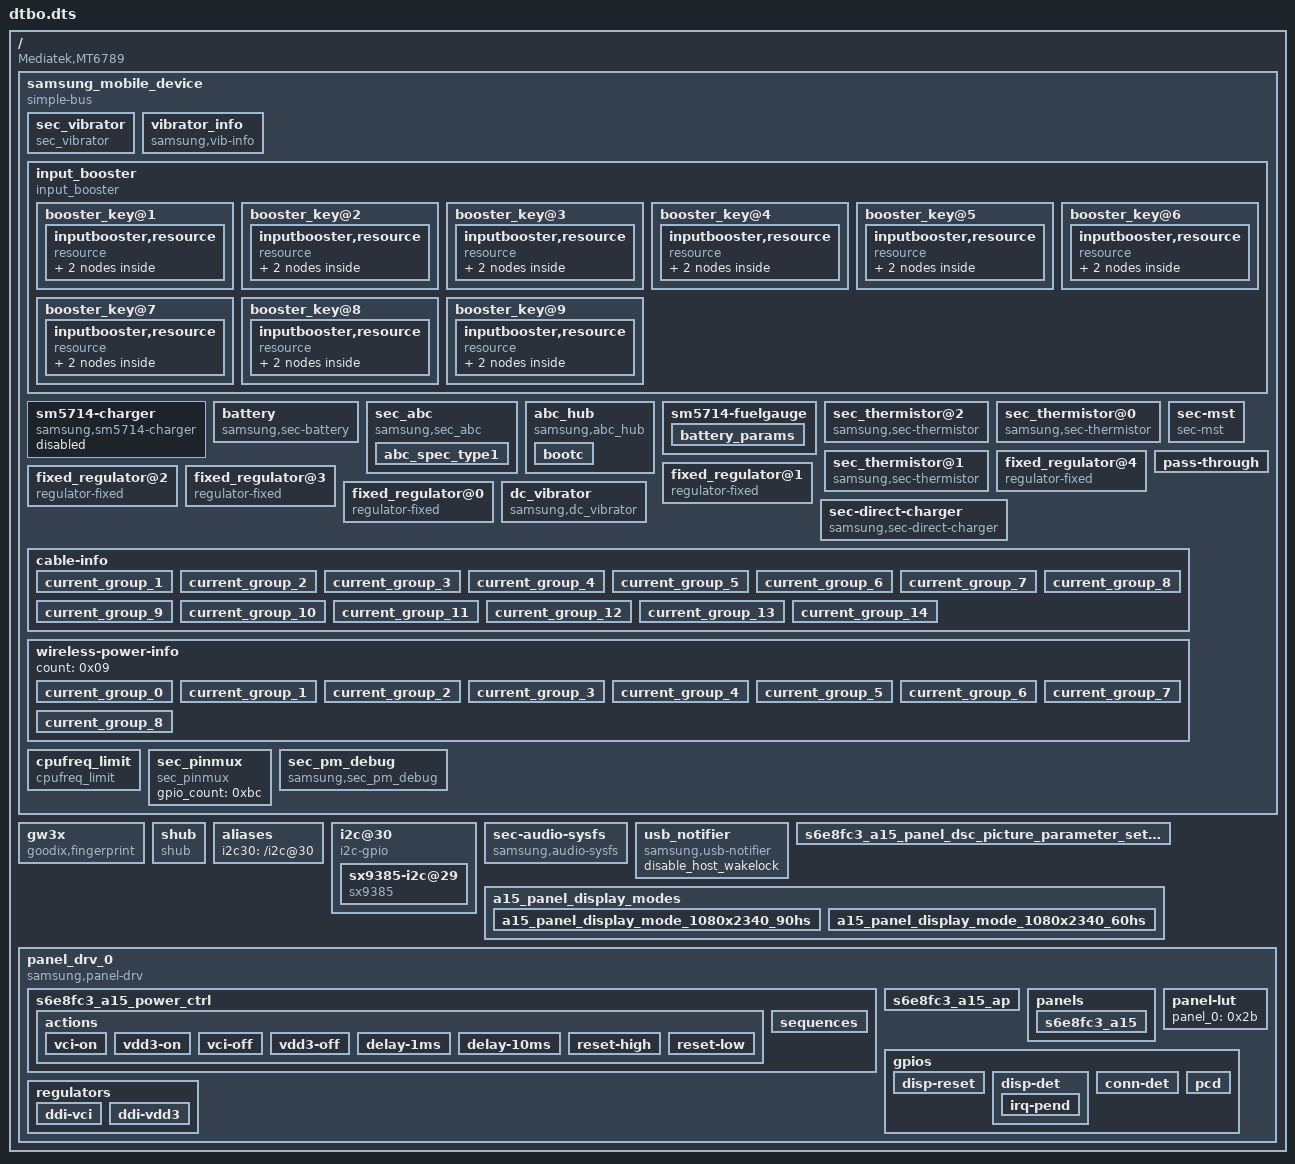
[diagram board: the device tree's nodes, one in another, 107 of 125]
/dts-v1/;

/ {
	compatible = "Mediatek,MT6789\0Samsung,A15 EUR OPEN 00";
	dtbo-hw_rev = <0x00>;
	dtbo-hw_rev_end = <0x03>;

	fragment@smd {
		target-path = "/";

		__overlay__ {

			samsung_mobile_device {
				compatible = "simple-bus";
				phandle = <0x80>;

				sec_vibrator {
					status = "okay";
					compatible = "sec_vibrator";
					haptic,normal_ratio = <0x64>;
					haptic,high_temp_ref = <0x30>;
					haptic,high_temp_ratio = <0x41>;
				};

				vibrator_info {
					status = "okay";
					compatible = "samsung,vib-info";
					functions = [00];
					samsung,intensities;
					samsung,haptic_intensities;
					phandle = <0x81>;
				};

				input_booster {
					status = "okay";
					compatible = "input_booster";
					resValcount = "2";
					max_resource_count = "3";
					max_cluster_count = "3";
					#address-cells = <0x01>;
					#size-cells = <0x00>;
					cpu_cluster_policy = "6,0";
					ib_release_values = "-1,16,0";
					allowed_resources = "0,1";

					booster_key@1 {
						input_booster,label = "key";
						input_booster,type = <0x00>;
						input_booster,head_time = <0xc8>;
						input_booster,tail_time = <0x00>;

						inputbooster,resource {
							compatible = "resource";

							resource@1 {
								resource,label = "CPU";
								resource,value = <0x137090 0x00>;
							};

							resource@2 {
								resource,label = "DDR";
								resource,value = <0x00 0x00>;
							};
						};
					};

					booster_key@2 {
						input_booster,label = "touchkey";
						input_booster,type = <0x01>;
						input_booster,head_time = <0x01>;
						input_booster,tail_time = <0x12c>;

						inputbooster,resource {
							compatible = "resource";

							resource@1 {
								resource,label = "CPU";
								resource,value = <0x00 0x106800>;
							};

							resource@2 {
								resource,label = "DDR";
								resource,value = <0x00 0x00>;
							};
						};
					};

					booster_key@3 {
						input_booster,label = "touch";
						input_booster,type = <0x02>;
						input_booster,head_time = <0x82>;
						input_booster,tail_time = <0x1f4>;

						inputbooster,resource {
							compatible = "resource";

							resource@1 {
								resource,label = "CPU";
								resource,value = <0x137090 0x106800>;
							};

							resource@2 {
								resource,label = "DDR";
								resource,value = <0x10aa 0x10aa>;
							};
						};
					};

					booster_key@4 {
						input_booster,label = "multitouch";
						input_booster,type = <0x03>;
						input_booster,head_time = <0x3e8>;
						input_booster,tail_time = <0x1f4>;

						inputbooster,resource {
							compatible = "resource";

							resource@1 {
								resource,label = "CPU";
								resource,value = <0x137090 0x106800>;
							};

							resource@2 {
								resource,label = "DDR";
								resource,value = <0x00 0x00>;
							};
						};
					};

					booster_key@5 {
						input_booster,label = "keyboard";
						input_booster,type = <0x04>;
						input_booster,head_time = <0x82>;
						input_booster,tail_time = <0x82>;

						inputbooster,resource {
							compatible = "resource";

							resource@1 {
								resource,label = "CPU";
								resource,value = <0x106800 0x106800>;
							};

							resource@2 {
								resource,label = "DDR";
								resource,value = <0x00 0x00>;
							};
						};
					};

					booster_key@6 {
						input_booster,label = "MOUSE";
						input_booster,type = <0x05>;
						input_booster,head_time = <0xc8>;
						input_booster,tail_time = <0x12c>;

						inputbooster,resource {
							compatible = "resource";

							resource@1 {
								resource,label = "CPU";
								resource,value = <0x137090 0x106800>;
							};

							resource@2 {
								resource,label = "DDR";
								resource,value = <0x00 0x00>;
							};
						};
					};

					booster_key@7 {
						input_booster,label = "mouse_wheel";
						input_booster,type = <0x06>;
						input_booster,head_time = <0xc8>;
						input_booster,tail_time = <0x00>;

						inputbooster,resource {
							compatible = "resource";

							resource@1 {
								resource,label = "CPU";
								resource,value = <0x137090 0x00>;
							};

							resource@2 {
								resource,label = "DDR";
								resource,value = <0x00 0x00>;
							};
						};
					};

					booster_key@8 {
						input_booster,label = "pen_hover";
						input_booster,type = <0x07>;
						input_booster,head_time = <0xc8>;
						input_booster,tail_time = <0x12c>;

						inputbooster,resource {
							compatible = "resource";

							resource@1 {
								resource,label = "CPU";
								resource,value = <0x137090 0x106800>;
							};

							resource@2 {
								resource,label = "DDR";
								resource,value = <0x00 0x00>;
							};
						};
					};

					booster_key@9 {
						input_booster,label = "pen";
						input_booster,type = <0x08>;
						input_booster,head_time = <0xc8>;
						input_booster,tail_time = <0x258>;

						inputbooster,resource {
							compatible = "resource";

							resource@1 {
								resource,label = "CPU";
								resource,value = <0x1a3ec0 0x106800>;
							};

							resource@2 {
								resource,label = "DDR";
								resource,value = <0x00 0x00>;
							};
						};
					};
				};

				sm5714-charger {
					status = "disable";
					compatible = "samsung,sm5714-charger";
					sm5714,chg_float_voltage_down_en = <0x01>;
					sm5714,chg_float_voltage_down_offset_mv = <0x14>;
					phandle = <0x82>;
				};

				battery {
					battery,otg_name = "sm5714-otg";
					battery,fgsrc_switch_name = "sm5714-fuelgauge";
					status = "okay";
					compatible = "samsung,sec-battery";
					battery,vendor = "Battery";
					battery,charger_name = "sec-direct-charger";
					battery,fuelgauge_name = "sm5714-fuelgauge";
					battery,technology = <0x02>;
					battery,chip_vendor = "MTK";
					battery,batt_data_version = <0x01>;
					battery,adc_check_count = <0x05>;
					battery,temp_check_type = <0x02>;
					battery,usb_temp_check_type = <0x02>;
					battery,chg_temp_check_type = <0x02>;
					battery,wpc_temp_check_type = <0x00>;
					battery,lrp_temp_check_type = <0x02>;
					battery,thermal_source = <0x02>;
					battery,usb_thermal_source = <0x02>;
					battery,chg_thermal_source = <0x02>;
					battery,wpc_thermal_source = <0x00>;
					battery,inbat_ocv_type = <0x00>;
					battery,polling_time = <0x0a 0x1e 0x1e 0x1e 0xe10>;
					battery,cable_check_type = <0x04>;
					battery,cable_source_type = <0x01>;
					battery,polling_type = <0x01>;
					battery,monitor_initial_count = <0x00>;
					battery,battery_check_type = <0x00>;
					battery,ovp_uvlo_check_type = <0x03>;
					battery,temp_check_count = <0x01>;
					battery,usb_protection_temp = <0x1f4>;
					battery,temp_gap_bat_usb = <0x96>;
					battery,overheatlimit_threshold = <0x2bc>;
					battery,overheatlimit_recovery = <0x2a8>;
					battery,wire_warm_overheat_thresh = <0x1f4>;
					battery,wire_normal_warm_thresh = <0x1a4>;
					battery,wire_cool1_normal_thresh = <0xb4>;
					battery,wire_cool2_cool1_thresh = <0x96>;
					battery,wire_cool3_cool2_thresh = <0x32>;
					battery,wire_cold_cool3_thresh = <0x00>;
					battery,wireless_warm_overheat_thresh = <0x1f4>;
					battery,wireless_normal_warm_thresh = <0x1a4>;
					battery,wireless_cool1_normal_thresh = <0xb4>;
					battery,wireless_cool2_cool1_thresh = <0x96>;
					battery,wireless_cool3_cool2_thresh = <0x32>;
					battery,wireless_cold_cool3_thresh = <0x00>;
					battery,tx_high_threshold = <0x1f4>;
					battery,tx_high_recovery = <0x1c2>;
					battery,tx_low_threshold = <0x00>;
					battery,tx_low_recovery = <0x32>;
					battery,wire_warm_current = <0xdac>;
					battery,wire_cool1_current = <0xc4e>;
					battery,wire_cool2_current = <0x47e>;
					battery,wire_cool3_current = <0x1c2>;
					battery,wireless_warm_current = <0x418>;
					battery,wireless_cool1_current = <0xc4a>;
					battery,wireless_cool2_current = <0x418>;
					battery,wireless_cool3_current = <0x1b5>;
					battery,full_check_type = <0x02>;
					battery,full_check_type_2nd = <0x02>;
					battery,full_check_count = <0x01>;
					battery,chg_gpio_full_check = <0x00>;
					battery,chg_polarity_full_check = <0x01>;
					battery,chg_high_temp = <0x24e>;
					battery,chg_high_temp_recovery = <0x226>;
					battery,chg_input_limit_current = <0x3e8>;
					battery,chg_charging_limit_current = <0x960>;
					battery,dchg_high_temp = <0x3e8 0x3e8 0x24e 0x24e>;
					battery,dchg_high_temp_recovery = <0x3e8 0x3e8 0x226 0x226>;
					battery,dchg_high_batt_temp = <0x3e8 0x3e8 0x3e8 0x3e8>;
					battery,dchg_high_batt_temp_recovery = <0x3e8 0x3e8 0x3e8 0x3e8>;
					battery,dchg_input_limit_current = <0x3e8>;
					battery,dchg_charging_limit_current = <0x7d0>;
					battery,wpc_temp_control_source = <0x01>;
					battery,wpc_high_temp = <0x190>;
					battery,wpc_high_temp_recovery = <0x17c>;
					battery,wpc_input_limit_current = <0x320>;
					battery,wpc_charging_limit_current = <0x3e8>;
					battery,wpc_temp_lcd_on_control_source = <0x01>;
					battery,wpc_lcd_on_input_limit_current = <0x320>;
					battery,wpc_store_high_temp = <0x168>;
					battery,wpc_store_high_temp_recovery = <0x154>;
					battery,wpc_store_charging_limit_current = <0x190>;
					battery,wpc_store_lcd_on_high_temp = <0x168>;
					battery,wpc_store_lcd_on_high_temp_rec = <0x12c>;
					battery,wpc_store_lcd_on_charging_limit_current = <0x190>;
					battery,fcc_by_tx = <0x4b0>;
					battery,sleep_mode_limit_current = <0x320>;
					battery,wc_full_input_limit_current = <0x64>;
					battery,ta_alert_wa;
					battery,mix_high_temp = <0x1a4>;
					battery,mix_high_chg_temp = <0x1f4>;
					battery,mix_high_temp_recovery = <0x186>;
					battery,mix_v2_lrp_recov = <0x1cc>;
					battery,mix_v2_lrp_cond = <0x1e0>;
					battery,mix_v2_bat_cond = <0x1e0>;
					battery,mix_v2_chg_cond = <0x00>;
					battery,mix_v2_dchg_cond = <0x00>;
					battery,full_condition_type = <0x09>;
					battery,full_condition_soc = <0x5d>;
					battery,recharge_check_count = <0x01>;
					battery,recharge_condition_type = <0x04>;
					battery,recharge_condition_soc = <0x62>;
					battery,charging_reset_time = <0x00>;
					battery,chg_float_voltage = <0x111c>;
					battery,pre_afc_work_delay = <0x7d0>;
					battery,pre_wc_afc_work_delay = <0xfa0>;
					battery,pre_afc_input_current = <0x1f4>;
					battery,pre_wc_afc_input_current = <0x1f4>;
					battery,swelling_high_rechg_voltage = <0xfa0>;
					battery,siop_icl = <0x4b0>;
					battery,siop_fcc = <0x708>;
					battery,siop_hv_icl = <0x2bc>;
					battery,siop_hv_icl_2nd = <0x226>;
					battery,siop_hv_fcc = <0x708>;
					battery,siop_apdo_icl = <0x3e8>;
					battery,siop_apdo_fcc = <0x7d0>;
					battery,siop_wpc_icl = <0x258>;
					battery,siop_wpc_fcc = <0x3e8 0x1f4 0x64>;
					battery,siop_hv_wpc_icl = <0x2bc>;
					battery,siop_hv_wpc_fcc = <0x3e8 0x1f4 0x64>;
					battery,siop_store_hv_wpc_icl = <0x1c2>;
					battery,store_mode_buckoff;
					battery,temp_table_LRP_45W = <0x181 0x16d>;
					battery,rp_current_rp1 = <0x1f4>;
					battery,rp_current_rp2 = <0x5dc>;
					battery,rp_current_rp3 = <0xbb8>;
					battery,rp_current_rdu_rp3 = <0x834>;
					battery,rp_current_abnormal_rp3 = <0x708>;
					battery,pd_charging_charge_power = <0x3a98>;
					battery,max_charging_current = <0xc4e>;
					battery,store_mode_charging_max = <0x46>;
					battery,store_mode_charging_min = <0x3c>;
					battery,wireless_cc_cv = <0x55>;
					battery,wireless_otg_input_current = <0x384>;
					battery,age_data_cycle = <0x00 0xc8 0xfa 0x12c 0x3e9>;
					battery,age_data_full_condition_soc = <0x5d 0x5c 0x5b 0x5a 0x59>;
					battery,age_data_common_offset = <0x00 0x14 0x28 0x3c 0x6e>;
					battery,age_data = <0x00 0x10fe 0x10b8 0x109a 0x5d 0x12c 0x10ea 0x10a4 0x1086 0x5c 0x190 0x10d6 0x1090 0x1072 0x5b 0x2bc 0x10c2 0x107c 0x105e 0x5a 0x3e8 0x1090 0x104a 0x102c 0x59>;
					battery,health_condition_cycle = <0x384 0x4b0 0x5dc>;
					battery,health_condition_asoc = <0x00 0x00 0x00>;
					battery,max_input_voltage = <0x2328>;
					battery,max_input_current = <0xbb8>;
					battery,cisd_alg_index = <0x08>;
					battery,cisd_max_voltage_thr = <0x1388>;
					battery,ignore_cisd_index = <0x00 0x00>;
					battery,ignore_cisd_index_d = <0x00 0x50>;
					battery,expired_time = <0x2580>;
					battery,recharging_expired_time = <0x1518>;
					battery,battery_full_capacity = <0x1388>;
					battery,ttf_capacity = <0x1324>;
					battery,cv_data = <0xe79 0x352 0x6cc 0xe56 0x366 0x668 0xbe0 0x37a 0x604 0x9ba 0x38e 0x582 0x77d 0x3a2 0x4d8 0x55a 0x3b6 0x3f2 0x416 0x3ca 0x2d0 0x289 0x3de 0xa5 0x1e4 0x3e8 0x00>;
					io-channels = <0xffffffff 0x03 0xffffffff 0x06 0xffffffff 0x05>;
					io-channel-names = "adc-temp\0adc-chg-temp\0adc-usb-temp\0n/a\0n/a\0n/a\0n/a\0n/a";
					pinctrl-names = "default";
					battery,adc_read_type = <0x01>;
					battery,dchg_temp_check_type = <0x02>;
					battery,dchg_thermal_source = <0x02>;
					battery,dctp_by_cgtp;
					battery,temp_adc_rsense = <0x0f>;
					battery,temp_table_adc = <0x65 0x71 0x8b 0xa5 0xc2 0xe1 0x10e 0x141 0x18d 0x1e4 0x242 0x2c8 0x358 0x402 0x4ca 0x59f 0x6a0 0x793 0x938 0xa93 0xbc4 0xd20 0xe29>;
					battery,temp_table_data = <0x384 0x352 0x320 0x2ee 0x2bc 0x28a 0x258 0x226 0x1f4 0x1c2 0x190 0x15e 0x12c 0xfa 0xc8 0x96 0x64 0x32 0x00 0xffffffce 0xffffff9c 0xffffff6a 0xffffff38>;
					battery,usb_temp_table_adc = <0x175 0x1ae 0x1f6 0x249 0x2a6 0x302 0x389 0x41b 0x4e2 0x5b7 0x68a 0x79c 0x8a1 0x9b3 0xacc 0xbcd 0xcde 0xdb1 0xef5 0xfd2 0x1026 0x1026 0x1026>;
					battery,usb_temp_table_data = <0x384 0x352 0x320 0x2ee 0x2bc 0x28a 0x258 0x226 0x1f4 0x1c2 0x190 0x15e 0x12c 0xfa 0xc8 0x96 0x64 0x32 0x00 0xffffffce 0xffffff9c 0xffffff6a 0xffffff38>;
					battery,chg_temp_table_adc = <0x168 0x19e 0x1e9 0x23a 0x296 0x2fb 0x380 0x410 0x4cd 0x59e 0x675 0x78c 0x891 0x9a6 0xabf 0xbbb 0xcd3 0xd9d 0xee1 0xfc5 0x1026 0x1026 0x1026>;
					battery,chg_temp_table_data = <0x384 0x352 0x320 0x2ee 0x2bc 0x28a 0x258 0x226 0x1f4 0x1c2 0x190 0x15e 0x12c 0xfa 0xc8 0x96 0x64 0x32 0x00 0xffffffce 0xffffff9c 0xffffff6a 0xffffff38>;
					battery,support_usb_conn_check;
					battery,mass_with_usb_thm;
					battery,temp_table_LRP_NORMAL = <0x190 0x186 0x186 0x17c 0x186 0x17c 0x17c 0x172 0x3e8 0x960 0x4b0 0x708>;
					battery,temp_table_LRP_25W = <0x19a 0x190 0x186 0x17c 0x190 0x186 0x17c 0x172 0x6a4 0xd48 0x44c 0x898>;
					battery,high_temp_float = <0x1036>;
					battery,low_temp_float = <0x111c>;
					battery,chg_ocp_current = <0x00>;
					battery,max_charging_charge_power = <0x61a8>;
					battery,age_data_by_common_offset;
					battery,step_chg_type = <0x00>;
					battery,dc_step_chg_type = <0xe9>;
					battery,dc_step_chg_charge_power = <0x55f0>;
					battery,dc_step_chg_step = <0x03>;
					battery,dc_step_chg_cond_vol = <0x1004 0x1068 0x111c>;
					battery,dc_step_chg_val_vfloat = <0x1004 0x1068 0x111c>;
					battery,dc_step_chg_val_iout = <0x15a4 0x12a2 0xeec>;
					battery,dc_step_chg_iin_check_cnt = <0x03>;
					battery,dc_step_chg_cond_soc = <0x19 0x35 0x64>;
					battery,standard_curr = <0xeec>;
					battery,ttf_hv_charge_current = <0x9cd>;
					battery,ttf_dc25_charge_current = <0x12c0>;
					battery,support_vpdo;
					battery,dchg_dc_in_swelling;
					battery,boosting_voltage_aicl;
					phandle = <0x83>;
				};

				sec_abc {
					compatible = "samsung,sec_abc";
					status = "okay";

					abc_spec_type1 {
						module_list = "gpu\0gpu_qc\0gpu_qc\0camera\0camera\0vib\0tsp\0tsp_sub\0mm\0camera\0camera\0camera\0camera\0camera\0camera\0camera\0camera\0camera";
						name_list = "gpu_fault\0gpu_fault\0gpu_page_fault\0mipi_overflow\0i2c_fail\0int_gnd_short\0tsp_int_fault\0tsp_int_fault\0venus_hung\0mipi_error_rw1\0mipi_error_rs1\0mipi_error_rt1\0mipi_error_fw1\0mipi_error_rt2\0mipi_error_uw1\0mipi_error_rm1\0mipi_error_rb1\0mipi_error_fs1";
						threshold_cnt = <0x14 0x02 0x14 0x01 0x01 0x19 0x0a 0x0a 0x0a 0x01 0x01 0x01 0x01 0x01 0x01 0x01 0x01 0x01>;
						threshold_time = <0x4b0 0x4b0 0x4b0 0x00 0x00 0x05 0x05 0x05 0x03 0x00 0x00 0x00 0x00 0x00 0x00 0x00 0x00 0x00>;
					};
				};

				abc_hub {
					compatible = "samsung,abc_hub";
					status = "okay";

					bootc {
						bootc,time_spec_user = <0x186a0>;
						bootc,time_spec_eng = <0x249f0>;
						bootc,time_spec_fac = <0x186a0>;
					};
				};

				sm5714-fuelgauge {
					status = "okay";
					fuelgauge,fuel_alert_soc = <0x01>;
					fuelgauge,capacity_max = <0x3e8>;
					fuelgauge,capacity_max_margin = <0x12c>;
					fuelgauge,capacity_min = <0x00>;
					fuelgauge,capacity_calculation_type = <0x1f>;
					fuelgauge,using_temp_compensation;
					fuelgauge,low_temp_limit = <0x64>;
					fuelgauge,using_hw_vempty;
					fuelgauge,sw_v_empty_voltage = <0xc80>;
					fuelgauge,sw_v_empty_voltage_cisd = <0xc1c>;
					fuelgauge,sw_v_empty_recover_voltage = <0xd98>;
					fuelgauge,capacity = <0xfa0>;
					fuelgauge,bat_id_gpio = <0xffffffff 0x6a 0x00 0xffffffff 0x1b 0x00>;
					phandle = <0x84>;

					battery_params {
						battery,id = <0x03>;
						battery3,battery_type = <0x111c 0x25fc>;
						battery3,battery_table0 = <0x1400 0x1b09 0x1b92 0x1c50 0x1cd1 0x1d2f 0x1d6a 0x1d7f 0x1d8f 0x1db7 0x1dee 0x1e39 0x1e6d 0x1ec1 0x1f07 0x1f51 0x1fbe 0x1fce 0x1ff8 0x2095 0x20b0 0x2152 0x229a 0x2400>;
						battery3,battery_table1 = <0x00 0xb3 0x133 0x24c 0x34c 0x44c 0x54c 0x766 0xc00 0xe80 0x13b3 0x1de6 0x2819 0x3266 0x3780 0x3a00 0x41b3 0x444c 0x46cc 0x4be6 0x4e80 0x5633 0x6400 0x64e6>;
						battery3,battery_table2 = <0x4a6f 0x383e 0x3234 0x2c2e 0x292a 0x2727 0x2628 0x2525 0x4a6f 0x383e 0x3234 0x2c2e 0x292a 0x2727 0x2628 0x2525>;
						battery3,rs_value = <0x48 0x48 0x3800 0x10a 0x599 0x599 0x50>;
						battery3,v_alarm = <0xc1c 0xc8>;
						battery3,topoff = <0x1ea>;
						battery3,i_cal = <0x01 0x00 0x800 0x800 0x00 0x00 0x7c9 0x800>;
						battery3,v_cal = <0x01 0x00 0x00 0x01 0x00 0x00 0x00>;
						battery3,temp_std = <0x19>;
						battery3,tem_poff = <0xd7a 0x32 0xd7a 0x32>;
						battery3,aux_ctrl = <0x322 0x5800>;
						battery3,data_ver = <0x02>;
						battery3,v_max_table = <0x229a 0x2271 0x2248 0x2220 0x21bf>;
						battery3,q_max_table = <0x25fc 0x25cf 0x25a2 0x2575 0x2277>;
						battery2,battery_type = <0x111c 0x2581>;
						battery2,battery_table0 = <0x1400 0x1ae0 0x1bd1 0x1c6d 0x1cde 0x1d38 0x1d6c 0x1d7f 0x1d89 0x1dda 0x1e15 0x1e41 0x1e6a 0x1ea4 0x1ef7 0x1f1f 0x1f68 0x1f9d 0x200a 0x2052 0x20eb 0x215c 0x22a8 0x2400>;
						battery2,battery_table1 = <0x00 0x80 0x199 0x299 0x3b3 0x4b3 0x5cc 0x7cc 0xb80 0x124c 0x1a19 0x1f4c 0x2719 0x2ee6 0x36b3 0x394c 0x3be6 0x3e80 0x464c 0x48e6 0x50b3 0x55e6 0x6400 0x64e6>;
						battery2,battery_table2 = <0x4862 0x383d 0x3234 0x2c2e 0x292a 0x2728 0x2627 0x2828 0x4862 0x383d 0x3234 0x2c2e 0x292a 0x2728 0x2627 0x2828>;
						battery2,rs_value = <0x48 0x48 0x3800 0x10a 0x599 0x599 0x50>;
						battery2,v_alarm = <0xc1c 0xc8>;
						battery2,topoff = <0x1ea>;
						battery2,i_cal = <0x01 0x00 0x800 0x800 0x00 0x00 0x7d8 0x800>;
						battery2,v_cal = <0x01 0x00 0x00 0x01 0x00 0x00 0x00>;
						battery2,temp_std = <0x19>;
						battery2,tem_poff = <0xd7a 0x32 0xd7a 0x32>;
						battery2,aux_ctrl = <0x322 0x5800>;
						battery2,data_ver = <0x03>;
						battery2,v_max_table = <0x22a8 0x227f 0x2256 0x222d 0x21cf>;
						battery2,q_max_table = <0x2581 0x2555 0x2529 0x24fc 0x2268>;
						battery1,battery_type = <0x111c 0x2525>;
						battery1,battery_table0 = <0x1400 0x1aad 0x1b4a 0x1c1c 0x1cab 0x1d10 0x1d5b 0x1d6c 0x1d7b 0x1d87 0x1ddb 0x1e17 0x1e42 0x1e90 0x1ed9 0x1f25 0x1f72 0x1f9e 0x1fee 0x207f 0x20e9 0x215a 0x22a5 0x2400>;
						battery1,battery_table1 = <0x00 0x66 0xe6 0x200 0x300 0x419 0x519 0x599 0x733 0xb66 0x1219 0x1a00 0x1f33 0x2c33 0x3400 0x3933 0x3be6 0x3e80 0x43b3 0x4b80 0x50b3 0x55e6 0x6400 0x64e6>;
						battery1,battery_table2 = <0x4965 0x383e 0x3134 0x2b2e 0x2729 0x2526 0x2424 0x2323 0x4965 0x383e 0x3134 0x2b2e 0x2729 0x2526 0x2424 0x2323>;
						battery1,rs_value = <0x48 0x48 0x3800 0x10a 0x599 0x599 0x50>;
						battery1,v_alarm = <0xc1c 0xc8>;
						battery1,topoff = <0x1ea>;
						battery1,i_cal = <0x01 0x00 0x800 0x800 0x00 0x00 0x7c9 0x800>;
						battery1,v_cal = <0x01 0x00 0x00 0x01 0x00 0x00 0x00>;
						battery1,temp_std = <0x19>;
						battery1,tem_poff = <0xd7a 0x32 0xd7a 0x32>;
						battery1,aux_ctrl = <0x322 0x5800>;
						battery1,data_ver = <0x03>;
						battery1,v_max_table = <0x22a5 0x227c 0x2253 0x222a 0x21ce>;
						battery1,q_max_table = <0x2525 0x24f9 0x24cd 0x24a1 0x21c1>;
					};
				};

				sec_thermistor@2 {
					compatible = "samsung,sec-thermistor";
					status = "okay";
					thermistor_name = "sec-wf-thermistor";
					id = <0x02>;
					io-channels = <0xffffffff 0x04>;
					io-channel-names = "wf_therm";
					io-channel-ranges;
					adc_array = <0x16a 0x19d 0x1ea 0x23c 0x297 0x2fd 0x37d 0x40c 0x4cd 0x59a 0x674 0x787 0x88f 0x99f 0xab9 0xbb6 0xcca 0xd9d 0xee1 0xfc2 0x1026 0x1026 0x1026>;
					temp_array = <0x384 0x352 0x320 0x2ee 0x2bc 0x28a 0x258 0x226 0x1f4 0x1c2 0x190 0x15e 0x12c 0xfa 0xc8 0x96 0x64 0x32 0x00 0xffffffce 0xffffff9c 0xffffff6a 0xffffff38>;
					phandle = <0x85>;
				};

				sec_thermistor@0 {
					compatible = "samsung,sec-thermistor";
					status = "okay";
					thermistor_name = "sec-ap-thermistor";
					id = <0x00>;
					io-channels = <0xffffffff 0x00>;
					io-channel-names = "ap_therm";
					io-channel-ranges;
					adc_array = <0x5e 0x6d 0x85 0x9c 0xb8 0xd7 0x106 0x139 0x178 0x1d1 0x22b 0x2b1 0x342 0x3ee 0x4ac 0x577 0x682 0x74a 0x8eb 0xa59 0xb99 0xd02 0xdfe>;
					temp_array = <0x384 0x352 0x320 0x2ee 0x2bc 0x28a 0x258 0x226 0x1f4 0x1c2 0x190 0x15e 0x12c 0xfa 0xc8 0x96 0x64 0x32 0x00 0xffffffce 0xffffff9c 0xffffff6a 0xffffff38>;
					phandle = <0x86>;
				};

				sec_thermistor@1 {
					compatible = "samsung,sec-thermistor";
					status = "okay";
					thermistor_name = "sec-pa-thermistor";
					id = <0x01>;
					io-channels = <0xffffffff 0x01>;
					io-channel-names = "pa_therm";
					io-channel-ranges;
					adc_array = <0x169 0x19a 0x1e9 0x23a 0x295 0x2fa 0x37e 0x40e 0x4cb 0x59a 0x675 0x784 0x88e 0x9a3 0xaba 0xbb4 0xccf 0xd95 0xedc 0xfc0 0x1026 0x1026 0x1026>;
					temp_array = <0x384 0x352 0x320 0x2ee 0x2bc 0x28a 0x258 0x226 0x1f4 0x1c2 0x190 0x15e 0x12c 0xfa 0xc8 0x96 0x64 0x32 0x00 0xffffffce 0xffffff9c 0xffffff6a 0xffffff38>;
					phandle = <0x87>;
				};

				sec-mst {
					compatible = "sec-mst";
					sec-mst,mst-pwr-gpio = <0xffffffff 0x04 0x00>;
					pinctrl-names = "default";
					pinctrl-0 = <0x01>;
					phandle = <0x88>;
				};

				fixed_regulator@4 {
					compatible = "regulator-fixed";
					regulator-name = "fixed_regulator${#}";
					gpio = <0xffffffff 0x69 0x00>;
					pinctrl-names = "default";
					pinctrl-0 = <0x02>;
					enable-active-high;
					phandle = <0x49>;
				};

				fixed_regulator@1 {
					compatible = "regulator-fixed";
					regulator-name = "fixed_regulator${#}";
					gpio = <0xffffffff 0x9e 0x00>;
					pinctrl-names = "default";
					pinctrl-0 = <0x03>;
					enable-active-high;
					phandle = <0x4e>;
				};

				fixed_regulator@2 {
					compatible = "regulator-fixed";
					regulator-name = "lcd_vddi";
					gpio = <0xffffffff 0x15 0x00>;
					pinctrl-names = "default";
					pinctrl-0 = <0x04>;
					enable-active-high;
					regulator-boot-on;
					phandle = <0x2c>;
				};

				fixed_regulator@3 {
					compatible = "regulator-fixed";
					regulator-name = "lcd_vdd3";
					gpio = <0xffffffff 0x98 0x00>;
					pinctrl-names = "default";
					pinctrl-0 = <0x05>;
					enable-active-high;
					regulator-boot-on;
					phandle = <0x2d>;
				};

				fixed_regulator@0 {
					compatible = "regulator-fixed";
					regulator-name = "fixed_regulator${#}";
					gpio = <0xffffffff 0x13 0x00>;
					pinctrl-names = "default";
					pinctrl-0 = <0x06>;
					enable-active-high;
					phandle = <0x46>;
				};

				sec-direct-charger {
					status = "okay";
					compatible = "samsung,sec-direct-charger";
					charger,battery_name = "battery";
					charger,main_charger = "sm5714-charger";
					charger,direct_charger = "sm5461-charger";
					charger,dchg_min_current = <0x7d0>;
					charger,ta_alert_wa;
				};

				pass-through {
					start_delay = <0x1388>;
					init_delay = <0x1388>;
					min_cap = <0xc8>;
					fixed_sc_cap = <0x384>;
					max_icl = <0xbb8>;
					vfloat = <0x111c>;
				};

				dc_vibrator {
					compatible = "samsung,dc_vibrator";
					status = "okay";
					dc_vib,motor_type = "COINDC";
					dc_vib,regulator_name = "dc_vib";
					dc_vib-supply = <0xffffffff>;
				};

				cable-info {
					default_input_current = <0x708>;
					default_charging_current = <0x834>;
					full_check_current_1st = <0x1ea>;
					full_check_current_2nd = <0xfa>;
					phandle = <0x89>;

					current_group_1 {
						cable_number = <0x02 0x13 0x15 0x16 0x17>;
						input_current = <0x1f4>;
						charging_current = <0x1f4>;
					};

					current_group_2 {
						cable_number = <0x19 0x1f>;
						input_current = <0x3e8>;
						charging_current = <0x3e8>;
					};

					current_group_3 {
						cable_number = <0x05 0x20>;
						input_current = <0x5dc>;
						charging_current = <0x5dc>;
					};

					current_group_4 {
						cable_number = <0x06 0x07 0x08 0x11 0x12>;
						input_current = <0x672>;
						charging_current = <0xc4e>;
					};

					current_group_5 {
						cable_number = <0x09>;
						input_current = <0x672>;
						charging_current = <0xc4e>;
					};

					current_group_6 {
						cable_number = <0x0a 0x0c 0x0f 0x1b 0x24>;
						input_current = <0x320>;
						charging_current = <0x92e>;
					};

					current_group_7 {
						cable_number = <0x0d>;
						input_current = <0x2bc>;
						charging_current = <0x92e>;
					};

					current_group_8 {
						cable_number = <0x18>;
						input_current = <0x3e8>;
						charging_current = <0x1c2>;
					};

					current_group_9 {
						cable_number = <0x1a>;
						input_current = <0x708>;
						charging_current = <0x708>;
					};

					current_group_10 {
						cable_number = <0x0b 0x0e 0x10 0x1c 0x23>;
						input_current = <0x28a>;
						charging_current = <0x92e>;
					};

					current_group_11 {
						cable_number = <0x1d 0x25>;
						input_current = <0x1f4>;
						charging_current = <0x4b0>;
					};

					current_group_12 {
						cable_number = <0x01 0x04 0x1e>;
						input_current = <0x1db>;
						charging_current = <0x226>;
					};

					current_group_13 {
						cable_number = <0x22>;
						input_current = <0x4b0>;
						charging_current = <0x92e>;
					};

					current_group_14 {
						cable_number = <0x21>;
						input_current = <0x320>;
						charging_current = <0x92e>;
					};
				};

				wireless-power-info {
					count = <0x09>;
					phandle = <0x8a>;

					current_group_0 {
						wireless_power_class = <0x02>;
						vout = <0x2328>;
						input_current_limit = <0x33e>;
						fast_charging_current = <0xc4e>;
						ttf_charge_current = <0x5dc>;
						rx_power = <0x1d4c>;
					};

					current_group_1 {
						wireless_power_class = <0x02>;
						vout = <0x2710>;
						input_current_limit = <0x2ee>;
						fast_charging_current = <0xc4e>;
						ttf_charge_current = <0x5dc>;
						rx_power = <0x1d4c>;
					};

					current_group_2 {
						wireless_power_class = <0x02>;
						vout = <0x2af8>;
						input_current_limit = <0x2a8>;
						fast_charging_current = <0xc4e>;
						ttf_charge_current = <0x5dc>;
						rx_power = <0x1d4c>;
					};

					current_group_3 {
						wireless_power_class = <0x02>;
						vout = <0x2ee0>;
						input_current_limit = <0x271>;
						fast_charging_current = <0xc4e>;
						ttf_charge_current = <0x5dc>;
						rx_power = <0x1d4c>;
					};

					current_group_4 {
						wireless_power_class = <0x02>;
						vout = <0x2328>;
						input_current_limit = <0x532>;
						fast_charging_current = <0xc4e>;
						ttf_charge_current = <0x87f>;
						rx_power = <0x2ee0>;
					};

					current_group_5 {
						wireless_power_class = <0x02>;
						vout = <0x2af8>;
						input_current_limit = <0x442>;
						fast_charging_current = <0xc4e>;
						ttf_charge_current = <0x834>;
						rx_power = <0x2ee0>;
					};

					current_group_6 {
						wireless_power_class = <0x02>;
						vout = <0x2ee0>;
						input_current_limit = <0x3e8>;
						fast_charging_current = <0xc4e>;
						ttf_charge_current = <0x834>;
						rx_power = <0x2ee0>;
					};

					current_group_7 {
						wireless_power_class = <0x02>;
						vout = <0x2af8>;
						input_current_limit = <0x550>;
						fast_charging_current = <0xc4e>;
						ttf_charge_current = <0x8fc>;
						rx_power = <0x3a98>;
					};

					current_group_8 {
						wireless_power_class = <0x02>;
						vout = <0x2ee0>;
						input_current_limit = <0x4e2>;
						fast_charging_current = <0xc4e>;
						ttf_charge_current = <0x8fc>;
						rx_power = <0x3a98>;
					};
				};

				cpufreq_limit {
					status = "okay";
					compatible = "cpufreq_limit";
					num_cpu = <0x08>;
					ltl_cpu_start = <0x00>;
					big_cpu_start = <0x06>;
					ltl_min_lock_freq = <0x118c30>;
					big_max_lock_freq = "\0\f5";
					ltl_divider = <0x04>;
				};

				sec_pinmux {
					status = "okay";
					compatible = "sec_pinmux";
					gpio_count = <0xbc>;
				};

				sec_pm_debug {
					status = "okay";
					compatible = "samsung,sec_pm_debug";
					thermal_zones = "soc_max\0cpu_little1\0cpu_little2\0cpu_little3\0cpu_little4\0cpu_big1\0cpu_big2\0cpu_big3\0cpu_big4\0gpu2\0gpu1\0soc1\0soc2\0md";
				};
			};

			gw3x {
				compatible = "goodix,fingerprint";
				reg = <0x00>;
				spi-max-frequency = <0x927c00>;
				clocks = <0xffffffff 0x7f 0xffffffff 0x12 0xffffffff 0x28>;
				clock-names = "parent-clk\0sel-clk\0spi-clk";
				pinctrl-names = "default\0pins_poweron\0pins_poweroff\0pins_poweron_tz\0pins_poweroff_tz";
				pinctrl-0 = <0x07 0x08 0x09>;
				pinctrl-1 = <0x0a 0x0b 0x0c 0x0d 0x0e>;
				pinctrl-2 = <0x09 0x0f 0x10 0x11 0x12>;
				pinctrl-3 = <0x0a>;
				pinctrl-4 = <0x09>;
				gpio-controller;
				#gpio-cells = <0x02>;
				goodix,gpio_pwr = <0xffffffff 0x66 0x00>;
				goodix,gpio_reset = <0xffffffff 0x65 0x00>;
				goodix,gpio_irq = <0xffffffff 0x11 0x00>;
				goodix,chip_id = "GW36T";
				goodix,orient = <0x00>;
				goodix,position = "50.8,14.16";
			};
		};
	};

	fragment@model {
		target-path = "/";

		__overlay__ {
			dtbo-hw_rev = <0x00>;
			dtbo-hw_rev_end = <0xff>;

			shub {
				pinctrl-names = "default";
				compatible = "shub";
				acc-motor-coef = <0x14>;
				acc-lis2dlc12-position = <0x0b>;
				mag-mxg4300s-position = <0x00>;
				mag-mxg4300s-array = [24 ba 00 f6 ff d6 00 2f 27 87 00 8c ff ae ff d2 28 77 00 00 00 00 00 00 00 00 00];
				mag-check-nfc = <0xffffffff 0x9a 0x00>;
				mag-mxg4300s-nfc-array = [24 4e 05 5b 02 b9 03 ba 25 ad fd 91 ff 5a ff 98 28 3f 00 00 00 00 00 00 00 00 00];
				light-position = <0x2a 0x3e 0x08 0x34 0x03 0x00>;
				brightness-array-len = <0x0b>;
				brightness-array = <0x13 0x30 0x36 0x3a 0x3f 0x43 0x46 0x49 0x4b 0x4d 0x64>;
			};

			aliases {
				i2c30 = "/i2c@30";
			};

			i2c@30 {
				cell-index = <0x1e>;
				compatible = "i2c-gpio";
				gpios = <0xffffffff 0x68 0x00 0xffffffff 0x67 0x00>;
				#i2c-gpio,delay-us = <0x02>;
				#address-cells = <0x01>;
				#size-cells = <0x00>;
				pinctrl-names = "default";
				pinctrl-0 = <0x13 0x14>;
				status = "okay";
				clock-frequency = <0x61a80>;
				phandle = <0x8b>;

				sx9385-i2c@29 {
					compatible = "sx9385";
					reg = <0x29>;
					status = "okay";
					pinctrl-names = "default";
					pinctrl-0 = <0x15 0x16>;
					interrupt-parent = <0xffffffff>;
					interrupts = <0x0c 0x00 0x00>;
					sx9385,ldo_en = <0xffffffff 0x54 0x00>;
					sx9385,nirq-gpio = <0xffffffff 0x0c 0x00>;
					sx9385,unknown_sel = <0x03>;
					sx9385,main-phases = <0x14>;
					sx9385,ref-phases = <0x0a>;
					sx9385,num_of_channels = <0x02>;
					sx9385,num_of_refs = <0x02>;
					sx9385,reg-num = <0x29>;
					sx9385,reg-init = [02 00 04 30 05 18 07 c0 08 11 0b 0a 0d 06 0e 66 47 56 4d 56 54 46 5a 46 48 05 4e 05 55 04 5b 04 49 27 4f 27 56 3f 5c 3f 79 12 7a 20 80 20 7b 60 7d 35 81 60 7c 4a 82 00 83 35 7e 14 84 80 7f 1b 91 00 92 00 9e 00 8c 00 4a 40 50 04 57 10 5d 01 09 78];
					phandle = <0x8c>;
				};
			};

			sec-audio-sysfs {
				compatible = "samsung,audio-sysfs";
				status = "okay";
			};

			usb_notifier {
				compatible = "samsung,usb-notifier";
				disable_host_wakelock;
			};
		};
	};

	fragment@panel_display_mode {
		target-path = "/";

		__overlay__ {

			s6e8fc3_a15_panel_dsc_picture_parameter_set_default {
				picture_parameter_set = <0x11000089 0x30800924 0x438002d 0x21c021c 0x200020e 0x20045a 0x7000c 0x22f0243 0x180010f0 0x30c2000 0x60b0b33 0xe1c2a38 0x46546269 0x7077797b 0x7d7e0102 0x1000940 0x9be19fc 0x19fa19f8 0x1a381a78 0x1ab62af6 0x2b342b74 0x3b746bf4 0x00 0x00 0x00 0x00 0x00 0x00 0x00 0x00 0x00 0x00>;
				phandle = <0x19>;
			};

			a15_panel_display_modes {
				native-mode = <0x17>;
				exposed-mode = <0x17 0x18>;
				phandle = <0x29>;

				a15_panel_display_mode_1080x2340_90hs {
					id = "1080x2340_90HS";
					width = <0x438>;
					height = <0x924>;
					refresh_rate = <0x5a>;
					refresh_mode = <0x01>;
					panel_refresh_rate = <0x5a>;
					panel_refresh_mode = <0x01>;
					panel_te_st = <0x00>;
					panel_te_ed = <0x00>;
					panel_te_sw_skip_count = <0x00>;
					panel_te_hw_skip_count = <0x00>;
					panel_video_mode;
					panel_h_porch = <0x3d 0xa2 0x22>;
					panel_v_porch = <0x0e 0x2c 0x02>;
					dsc_en = <0x01>;
					dsc_cnt = <0x01>;
					dsc_slice_num = <0x02>;
					dsc_slice_w = <0x21c>;
					dsc_slice_h = <0x75>;
					dsc_picture_parameter_set = <0x19>;
					cmd_lp_ref = <0x6e1>;
					disp_qos_fps = <0x5a>;
					phandle = <0x17>;
				};

				a15_panel_display_mode_1080x2340_60hs {
					id = "1080x2340_60HS";
					width = <0x438>;
					height = <0x924>;
					refresh_rate = <0x3c>;
					refresh_mode = <0x01>;
					panel_refresh_rate = <0x3c>;
					panel_refresh_mode = <0x01>;
					panel_te_st = <0x00>;
					panel_te_ed = <0x00>;
					panel_te_sw_skip_count = <0x00>;
					panel_te_hw_skip_count = <0x00>;
					panel_video_mode;
					panel_h_porch = <0x3d 0xa2 0x22>;
					panel_v_porch = <0x0e 0x4dc 0x02>;
					dsc_en = <0x01>;
					dsc_cnt = <0x01>;
					dsc_slice_num = <0x02>;
					dsc_slice_w = <0x21c>;
					dsc_slice_h = <0x75>;
					dsc_picture_parameter_set = <0x19>;
					cmd_lp_ref = <0x1d32>;
					disp_qos_fps = <0x5a>;
					phandle = <0x18>;
				};
			};
		};
	};

	fragment@panel_drv {
		target-path = "/";

		__overlay__ {

			panel_drv_0 {
				status = "okay";
				compatible = "samsung,panel-drv";
				panel,id = <0x00>;
				pinctrl-names = "default";
				pinctrl-0 = <0x1a 0x1b 0x1c>;
				phandle = <0x8d>;

				s6e8fc3_a15_power_ctrl {
					phandle = <0x2a>;

					actions {

						vci-on {
							type = <0x03>;
							reg = <0x1d>;
							phandle = <0x20>;
						};

						vdd3-on {
							type = <0x03>;
							reg = <0x1e>;
							phandle = <0x21>;
						};

						vci-off {
							type = <0x04>;
							reg = <0x1d>;
							phandle = <0x26>;
						};

						vdd3-off {
							type = <0x04>;
							reg = <0x1e>;
							phandle = <0x27>;
						};

						delay-1ms {
							type = <0x01>;
							value = <0x01>;
							phandle = <0x22>;
						};

						delay-10ms {
							type = <0x01>;
							value = <0x0a>;
							phandle = <0x23>;
						};

						reset-high {
							type = <0x07>;
							gpio = <0x1f>;
							phandle = <0x24>;
						};

						reset-low {
							type = <0x08>;
							gpio = <0x1f>;
							phandle = <0x25>;
						};
					};

					sequences {
						panel_boot_on = <0x20 0x21>;
						panel_power_on = <0x21 0x22 0x20 0x23 0x24 0x23 0x25 0x23 0x24 0x23>;
						panel_power_off = <0x25 0x22 0x26 0x23 0x27>;
					};
				};

				s6e8fc3_a15_ap {
					MTK,size = <0x45 0x95>;
					MTK,timing,dsi-hs-clk = <0x382>;
					MTK,data_lane = <0x04>;
					MTK,phy_timcon-lpx = <0x07>;
					MTK,disable_rdma_underflow = <0x01>;
					phandle = <0x28>;
				};

				panels {

					s6e8fc3_a15 {
						ap-vendor-setting = <0x28>;
						display-mode = <0x29>;
						power-ctrl = <0x2a>;
						dqe-suffix = "s6e8fc3_a15";
						id-mask = <0x00 0x00>;
						phandle = <0x2b>;
					};
				};

				panel-lut {
					panel_0 = <0x2b>;
				};

				gpios {

					disp-reset {
						gpios = <0xffffffff 0x55 0x01>;
						dir = <0x00>;
						irq-type = <0x00>;
						phandle = <0x1f>;
					};

					disp-det {
						gpios = <0xffffffff 0x06 0x01>;
						dir = <0x01>;
						irq-type = <0x02>;
						phandle = <0x8e>;

						irq-pend {
							reg = <0x00 0x15850a34 0x00>;
							bit = <0x02>;
						};
					};

					conn-det {
						gpios = <0xffffffff 0x23 0x00>;
						dir = <0x01>;
						irq-type = <0x2001>;
						phandle = <0x8f>;
					};

					pcd {
						gpios = <0xffffffff 0x0e 0x01>;
						dir = <0x01>;
						irq-type = <0x02>;
						phandle = <0x90>;
					};
				};

				regulators {

					ddi-vci {
						regulator = <0x2c>;
						type = <0x01>;
						def-voltage = <0x2dc6c0>;
						phandle = <0x1d>;
					};

					ddi-vdd3 {
						regulator = <0x2d>;
						type = <0x01>;
						def-voltage = <0x1b7740>;
						phandle = <0x1e>;
					};
				};
			};
		};
	};

	fragment@0 {
		target = <0xffffffff>;

		__overlay__ {
		};
	};

	fragment@1 {
		target = <0xffffffff>;

		__overlay__ {
			headset-use-ap-eint = <0x00>;
			headset-eint-num = <0x00>;
			no-use-comparator = <0x01>;
			headset-key-mode = <0x01>;
			headset-vol-threshold = <0x00 0x24e 0x24f 0x7d0 0xa28>;
			headset-three-key-threshold = <0x00 0xa3 0x116 0x1f5>;
			headset-four-key-threshold = <0x00 0xa3 0xc4 0x116 0x1f5>;
			moisture_use_ext_res = <0x01>;
			moisture-water-r = <0xc350>;
			moisture-vm = <0x64>;
		};
	};

	fragment@2 {
		target = <0xffffffff>;

		__overlay__ {
			compatible = "mediatek,disp-leds";

			backlight {
				led_mode = <0x04>;
			};
		};
	};

	fragment@3 {
		target = <0xffffffff>;

		__overlay__ {

			lcm_led_en1_gpio {
				phandle = <0x2e>;

				pins_cmd_dat {
					pinmux = <0xc00>;
					slew-rate = <0x01>;
					output-high;
				};
			};

			lcm_led_en0_gpio {
				phandle = <0x2f>;

				pins_cmd_dat {
					pinmux = <0xc00>;
					slew-rate = <0x01>;
					output-low;
				};
			};

			lcm_rst_out1_gpio {
				phandle = <0x30>;

				pins_cmd_dat {
					pinmux = <0x5500>;
					slew-rate = <0x01>;
					output-high;
				};
			};

			lcm_rst_out0_gpio {
				phandle = <0x31>;

				pins_cmd_dat {
					pinmux = <0x5500>;
					slew-rate = <0x01>;
					output-low;
				};
			};

			lcm_dsi_te {
				phandle = <0x32>;

				pins_cmd_dat {
					pinmux = <0x5301>;
				};
			};
		};
	};

	fragment@4 {
		target = <0xffffffff>;

		__overlay__ {
			pinctrl-names = "lcm_led_en1_gpio\0lcm_led_en0_gpio\0lcm_rst_out1_gpio\0lcm_rst_out0_gpio\0mode_te_te";
			pinctrl-0 = <0x2e>;
			pinctrl-1 = <0x2f>;
			pinctrl-2 = <0x30>;
			pinctrl-3 = <0x31>;
			pinctrl-4 = <0x32>;
			status = "okay";
		};
	};

	fragment@5 {
		target = <0xffffffff>;

		__overlay__ {
			pinctrl-names = "lcm_rst_out1_gpio\0lcm_rst_out0_gpio\0mode_te_te";
			pinctrl-0 = <0x30>;
			pinctrl-1 = <0x31>;
			pinctrl-2 = <0x32>;
			status = "okay";
		};
	};

	fragment@6 {
		target = <0xffffffff>;

		__overlay__ {
			status = "okay";
			#address-cells = <0x01>;
			#size-cells = <0x00>;

			panel@0 {
				compatible = "s6e8fc3,fhdp,s2dos15a01,vdo";
				reg = <0x00>;
				reset-gpios = <0xffffffff 0x55 0x00>;
				tsp-3p0-en-gpios = <0xffffffff 0x13 0x00>;
				lcd-3p0-en-gpios = <0xffffffff 0x15 0x00>;
				lcd-1p8-en-gpios = <0xffffffff 0x98 0x00>;
				pinctrl-names = "default";

				port {

					endpoint {
						remote-endpoint = <0x33>;
						phandle = <0x34>;
					};
				};
			};

			ports {

				port {

					endpoint {
						remote-endpoint = <0x34>;
						phandle = <0x33>;
					};
				};
			};
		};
	};

	fragment@7 {
		target = <0xffffffff>;

		__overlay__ {

			gps_default {
				phandle = <0x35>;
			};

			gps_l1_lna@0 {
				phandle = <0x36>;

				pins_cmd_dat {
					pinmux = <0x1900>;
					output-low;
				};
			};

			gps_l1_lna@1 {
				phandle = <0x37>;

				pins_cmd_dat {
					pinmux = <0x1902>;
				};
			};

			gps_l1_lna@2 {
				phandle = <0x38>;

				pins_cmd_dat {
					pinmux = <0x1900>;
					output-high;
				};
			};

			gps_l5_lna@0 {
				phandle = <0x39>;

				pins_cmd_dat {
					pinmux = <0x1a00>;
					output-low;
				};
			};

			gps_l5_lna@1 {
				phandle = <0x3a>;

				pins_cmd_dat {
					pinmux = <0x1a02>;
				};
			};

			gps_l5_lna@2 {
				phandle = <0x3b>;

				pins_cmd_dat {
					pinmux = <0x1a00>;
					output-high;
				};
			};
		};
	};

	fragment@8 {
		target = <0xffffffff>;

		__overlay__ {
			pinctrl-names = "default\0gps_l1_lna_disable\0gps_l1_lna_dsp_ctrl\0gps_l1_lna_enable\0gps_l5_lna_disable\0gps_l5_lna_dsp_ctrl\0gps_l5_lna_enable";
			pinctrl-0 = <0x35>;
			pinctrl-1 = <0x36>;
			pinctrl-2 = <0x37>;
			pinctrl-3 = <0x38>;
			pinctrl-4 = <0x39>;
			pinctrl-5 = <0x3a>;
			pinctrl-6 = <0x3b>;
			status = "okay";
		};
	};

	fragment@9 {
		target = <0xffffffff>;

		__overlay__ {

			lm3643@63 {
				compatible = "mediatek,lm3643";
				reg = <0x63>;
				#cooling-cells = <0x02>;
				pinctrl-names = "default\0hwen_high\0hwen_low";
				pinctrl-0 = <0x3c>;
				pinctrl-1 = <0x3d>;
				pinctrl-2 = <0x3e>;
				status = "okay";
				phandle = <0x91>;

				flash@0 {
					reg = <0x00>;
					type = <0x00>;
					ct = <0x00>;
					part = <0x00>;

					port@0 {

						endpoint {
							remote-endpoint = <0x3f>;
							phandle = <0x41>;
						};
					};
				};

				flash@1 {
					reg = <0x01>;
					type = <0x00>;
					ct = <0x01>;
					part = <0x00>;

					port@1 {

						endpoint {
							remote-endpoint = <0x40>;
							phandle = <0x42>;
						};
					};
				};
			};
		};
	};

	fragment@10 {
		target = <0xffffffff>;

		__overlay__ {

			default {
				phandle = <0x3c>;
			};

			hwen_high {
				phandle = <0x3d>;

				pins_cmd_dat {
					pinmux = <0x9d00>;
					slew-rate = <0x01>;
					output-high;
				};
			};

			hwen_low {
				phandle = <0x3e>;

				pins_cmd_dat {
					pinmux = <0x9d00>;
					slew-rate = <0x01>;
					output-low;
				};
			};
		};
	};

	fragment@11 {
		target = <0xffffffff>;

		__overlay__ {

			port@0 {

				endpoint {
					remote-endpoint = <0x41>;
					phandle = <0x3f>;
				};
			};

			port@1 {

				endpoint {
					remote-endpoint = <0x42>;
					phandle = <0x40>;
				};
			};
		};
	};

	fragment@12 {
		target = <0xffffffff>;

		__overlay__ {

			camera_main_af@72 {
				compatible = "mediatek,camera_main_af";
				reg = <0x72>;
				status = "okay";
				phandle = <0x92>;
			};
		};
	};

	fragment@13 {
		target = <0xffffffff>;

		__overlay__ {

			camera_main_two_af@0d {
				compatible = "mediatek,camera_main_two_af";
				reg = <0x0d>;
				status = "okay";
				phandle = <0x93>;
			};

			camera_main_three_af@0c {
				compatible = "mediatek,camera_main_three_af";
				reg = <0x0c>;
				status = "okay";
				phandle = <0x94>;
			};
		};
	};

	fragment@14 {
		target = <0xffffffff>;

		__overlay__ {
			camaf_m1_pmic-supply = <0xffffffff>;
			camaf_m2_pmic-supply = <0xffffffff>;
			camaf_m3_pmic-supply = <0xffffffff>;
			status = "okay";
		};
	};

	fragment@15 {
		target = <0xffffffff>;

		__overlay__ {
			scp_spk_process_enable = <0x00 0x04 0x0f 0x13>;
			status = "okay";
		};
	};

	fragment@16 {
		target = <0xffffffff>;

		__overlay__ {
			mediatek,spk-i2s = <0x03 0x00>;

			mediatek,speaker-codec {
			};
		};
	};

	fragment@17 {
		target = <0xffffffff>;

		__overlay__ {
			status = "okay";
		};
	};

	fragment@18 {
		target = <0xffffffff>;

		__overlay__ {
			pd_vbus_upper_bound = <0xb71b00>;
		};
	};

	fragment@19 {
		target = <0xffffffff>;

		__overlay__ {
			fixed_thermal;
		};
	};

	fragment@20 {
		target = <0xffffffff>;

		__overlay__ {
			DISABLE_MTKBATTERY = <0x01>;
		};
	};

	fragment@21 {
		target = <0xffffffff>;

		__overlay__ {
			disable_charger;
		};
	};

	fragment@22 {
		target = <0xffffffff>;

		__overlay__ {

			MTEE {
				compatible = "mediatek,mtk_svp_on_mtee_support";
				phandle = <0x95>;
			};

			SecureVideoPath {
				compatible = "mediatek,mtk_sec_video_path_support";
				phandle = <0x96>;
			};
		};
	};

	fragment@23 {
		target = <0xffffffff>;

		__overlay__ {
			status = "disabled";
		};
	};

	fragment@24 {
		target = <0xffffffff>;

		__overlay__ {
			sec-sd-slot-type = <0x03>;
			vmmc-supply = <0xffffffff>;
		};
	};

	fragment@25 {
		target = <0xffffffff>;

		__overlay__ {
			GPIO_SIM1_HOT_PLUG = <0xffffffff 0x17 0x00>;
			GPIO_SIM1_SCLK = <0xffffffff 0x4d 0x00>;
			GPIO_SIM1_SRST = <0xffffffff 0x4e 0x00>;
			GPIO_SIM1_SIO = <0xffffffff 0x4f 0x00>;
			GPIO_SIM2_SCLK = <0xffffffff 0x50 0x00>;
			GPIO_SIM2_SRST = <0xffffffff 0x51 0x00>;
			GPIO_SIM2_SIO = <0xffffffff 0x52 0x00>;
			GPIO_FDD_BAND_SUPPORT_DETECT_1ST_PIN = <0xffffffff 0x6d 0x00>;
			GPIO_FDD_BAND_SUPPORT_DETECT_2ND_PIN = <0xffffffff 0x6e 0x00>;
			GPIO_FDD_BAND_SUPPORT_DETECT_3RD_PIN = <0xffffffff 0x6f 0x00>;
		};
	};

	fragment@26 {
		target = <0xffffffff>;

		__overlay__ {
			gpio_init_default = <0x00 0x00 0x00 0x00 0x01 0x00 0x00 0x01 0x00 0x00 0x00 0x00 0x00 0x01 0x02 0x00 0x00 0x00 0x00 0x00 0x01 0x03 0x00 0x00 0x00 0x00 0x00 0x01 0x04 0x00 0x00 0x00 0x01 0x00 0x01 0x05 0x00 0x00 0x00 0x01 0x00 0x01 0x06 0x00 0x00 0x00 0x01 0x00 0x00 0x07 0x00 0x00 0x00 0x00 0x00 0x01 0x08 0x00 0x00 0x00 0x00 0x00 0x01 0x09 0x00 0x00 0x00 0x01 0x01 0x01 0x0a 0x00 0x00 0x00 0x00 0x00 0x01 0x0b 0x00 0x00 0x00 0x00 0x00 0x01 0x0c 0x00 0x00 0x00 0x00 0x00 0x01 0x0d 0x06 0x00 0x00 0x01 0x00 0x01 0x0e 0x00 0x00 0x00 0x01 0x00 0x00 0x0f 0x00 0x01 0x00 0x01 0x00 0x00 0x10 0x00 0x01 0x00 0x01 0x00 0x00 0x11 0x00 0x00 0x00 0x00 0x00 0x00 0x12 0x00 0x01 0x00 0x01 0x00 0x00 0x13 0x00 0x01 0x01 0x01 0x00 0x00 0x14 0x00 0x00 0x00 0x01 0x00 0x00 0x15 0x00 0x01 0x00 0x00 0x02 0x00 0x16 0x00 0x01 0x00 0x01 0x00 0x00 0x17 0x01 0x00 0x00 0x00 0x00 0x00 0x18 0x00 0x00 0x00 0x01 0x00 0x00 0x19 0x02 0x00 0x00 0x01 0x00 0x01 0x1a 0x00 0x00 0x00 0x01 0x00 0x01 0x1b 0x00 0x00 0x00 0x01 0x01 0x00 0x1c 0x01 0x00 0x00 0x01 0x01 0x01 0x1d 0x01 0x00 0x00 0x00 0x00 0x01 0x1e 0x00 0x00 0x00 0x01 0x00 0x01 0x1f 0x00 0x00 0x00 0x01 0x00 0x01 0x20 0x00 0x00 0x00 0x01 0x00 0x01 0x21 0x00 0x00 0x00 0x01 0x00 0x01 0x22 0x00 0x00 0x00 0x01 0x00 0x00 0x23 0x00 0x00 0x00 0x00 0x02 0x00 0x24 0x00 0x00 0x00 0x01 0x00 0x00 0x25 0x00 0x00 0x00 0x01 0x00 0x00 0x26 0x02 0x00 0x00 0x00 0x00 0x01 0x27 0x02 0x00 0x00 0x00 0x00 0x01 0x28 0x02 0x00 0x00 0x00 0x00 0x01 0x29 0x02 0x00 0x00 0x01 0x00 0x01 0x2a 0x00 0x01 0x00 0x01 0x00 0x00 0x2b 0x00 0x01 0x00 0x01 0x00 0x00 0x2c 0x00 0x01 0x00 0x01 0x00 0x00 0x2d 0x00 0x01 0x00 0x01 0x00 0x00 0x2e 0x06 0x00 0x00 0x01 0x00 0x00 0x2f 0x06 0x00 0x00 0x01 0x00 0x00 0x30 0x06 0x00 0x00 0x00 0x00 0x00 0x31 0x06 0x00 0x00 0x01 0x00 0x00 0x32 0x02 0x00 0x00 0x00 0x00 0x01 0x33 0x02 0x00 0x00 0x00 0x00 0x01 0x34 0x02 0x00 0x00 0x00 0x00 0x01 0x35 0x02 0x00 0x00 0x01 0x00 0x01 0x36 0x00 0x00 0x00 0x01 0x00 0x00 0x37 0x00 0x00 0x00 0x01 0x00 0x00 0x38 0x00 0x00 0x00 0x01 0x00 0x00 0x39 0x00 0x00 0x00 0x01 0x00 0x00 0x3a 0x00 0x00 0x00 0x01 0x00 0x00 0x3b 0x00 0x00 0x00 0x01 0x00 0x00 0x3c 0x00 0x00 0x00 0x01 0x00 0x00 0x3d 0x00 0x00 0x00 0x01 0x00 0x00 0x3e 0x00 0x00 0x00 0x01 0x00 0x00 0x3f 0x00 0x00 0x00 0x01 0x00 0x00 0x40 0x00 0x00 0x00 0x01 0x00 0x00 0x41 0x00 0x00 0x00 0x01 0x00 0x00 0x42 0x01 0x00 0x00 0x01 0x01 0x00 0x43 0x01 0x00 0x00 0x01 0x01 0x01 0x44 0x05 0x00 0x00 0x00 0x00 0x01 0x45 0x00 0x00 0x00 0x01 0x00 0x01 0x4d 0x01 0x00 0x00 0x00 0x00 0x01 0x4e 0x01 0x00 0x00 0x00 0x00 0x01 0x4f 0x01 0x00 0x00 0x01 0x01 0x01 0x50 0x01 0x00 0x00 0x00 0x00 0x01 0x51 0x01 0x00 0x00 0x00 0x00 0x01 0x52 0x01 0x00 0x00 0x01 0x01 0x01 0x53 0x00 0x00 0x00 0x01 0x00 0x00 0x54 0x00 0x00 0x00 0x01 0x00 0x01 0x55 0x00 0x01 0x00 0x00 0x02 0x00 0x56 0x00 0x00 0x00 0x01 0x00 0x00 0x57 0x01 0x00 0x00 0x01 0x00 0x00 0x58 0x00 0x00 0x00 0x01 0x00 0x00 0x59 0x00 0x00 0x00 0x01 0x00 0x00 0x5a 0x00 0x00 0x00 0x01 0x00 0x00 0x5b 0x01 0x00 0x00 0x00 0x00 0x00 0x5c 0x01 0x00 0x00 0x00 0x00 0x00 0x5d 0x01 0x00 0x00 0x00 0x00 0x00 0x5e 0x01 0x00 0x00 0x00 0x00 0x00 0x5f 0x01 0x00 0x00 0x00 0x00 0x00 0x60 0x00 0x00 0x00 0x01 0x00 0x00 0x61 0x01 0x00 0x00 0x00 0x00 0x00 0x62 0x01 0x00 0x00 0x00 0x00 0x00 0x63 0x01 0x00 0x00 0x00 0x00 0x00 0x64 0x00 0x00 0x00 0x01 0x00 0x00 0x65 0x00 0x01 0x00 0x01 0x00 0x00 0x66 0x00 0x01 0x00 0x01 0x00 0x00 0x67 0x00 0x00 0x00 0x00 0x00 0x00 0x68 0x00 0x00 0x00 0x00 0x00 0x00 0x69 0x00 0x01 0x00 0x01 0x00 0x00 0x6a 0x00 0x00 0x00 0x01 0x01 0x00 0x6b 0x00 0x00 0x00 0x01 0x00 0x00 0x6c 0x00 0x00 0x00 0x01 0x00 0x00 0x6d 0x00 0x00 0x00 0x00 0x00 0x01 0x6e 0x00 0x00 0x00 0x00 0x00 0x01 0x6f 0x00 0x00 0x00 0x00 0x00 0x01 0x70 0x01 0x00 0x00 0x00 0x00 0x00 0x71 0x01 0x00 0x00 0x01 0x00 0x00 0x72 0x01 0x00 0x00 0x00 0x00 0x00 0x73 0x01 0x00 0x00 0x01 0x00 0x00 0x74 0x01 0x00 0x00 0x00 0x00 0x00 0x75 0x01 0x00 0x00 0x01 0x00 0x00 0x76 0x01 0x00 0x00 0x00 0x00 0x00 0x77 0x01 0x00 0x00 0x01 0x00 0x00 0x78 0x01 0x00 0x00 0x00 0x00 0x00 0x79 0x01 0x00 0x00 0x01 0x00 0x00 0x7a 0x01 0x00 0x00 0x00 0x00 0x00 0x7b 0x01 0x00 0x00 0x00 0x00 0x00 0x7c 0x01 0x00 0x00 0x01 0x00 0x00 0x7d 0x01 0x00 0x00 0x01 0x00 0x00 0x7e 0x01 0x01 0x00 0x01 0x00 0x00 0x7f 0x01 0x01 0x00 0x01 0x00 0x00 0x80 0x01 0x01 0x00 0x01 0x00 0x00 0x81 0x01 0x01 0x00 0x01 0x00 0x00 0x82 0x01 0x00 0x00 0x01 0x01 0x01 0x83 0x01 0x00 0x00 0x01 0x01 0x01 0x84 0x02 0x00 0x00 0x00 0x00 0x01 0x85 0x02 0x00 0x00 0x00 0x00 0x01 0x86 0x01 0x00 0x00 0x01 0x01 0x01 0x87 0x01 0x00 0x00 0x01 0x01 0x01 0x88 0x01 0x00 0x00 0x00 0x00 0x01 0x89 0x01 0x00 0x00 0x00 0x00 0x01 0x8a 0x01 0x00 0x00 0x01 0x01 0x01 0x8b 0x01 0x00 0x00 0x01 0x01 0x01 0x8c 0x01 0x00 0x00 0x00 0x00 0x01 0x8d 0x01 0x00 0x00 0x00 0x00 0x01 0x8e 0x01 0x00 0x00 0x01 0x01 0x01 0x8f 0x01 0x00 0x00 0x01 0x01 0x01 0x90 0x01 0x00 0x00 0x01 0x01 0x01 0x91 0x01 0x00 0x00 0x01 0x01 0x01 0x92 0x01 0x00 0x00 0x01 0x01 0x01 0x93 0x01 0x00 0x00 0x01 0x01 0x01 0x94 0x01 0x00 0x00 0x01 0x01 0x01 0x95 0x01 0x00 0x00 0x01 0x01 0x01 0x96 0x00 0x01 0x00 0x01 0x00 0x01 0x97 0x00 0x01 0x00 0x01 0x00 0x01 0x98 0x00 0x01 0x00 0x00 0x02 0x00 0x99 0x00 0x00 0x00 0x01 0x00 0x01 0x9a 0x00 0x00 0x00 0x00 0x00 0x01 0x9b 0x00 0x01 0x00 0x01 0x00 0x01 0x9c 0x00 0x01 0x00 0x01 0x00 0x01 0x9d 0x00 0x01 0x01 0x00 0x00 0x01 0x9e 0x00 0x01 0x00 0x01 0x00 0x00 0x9f 0x00 0x00 0x00 0x01 0x00 0x00 0xa0 0x01 0x00 0x00 0x00 0x00 0x01 0xa1 0x01 0x00 0x00 0x00 0x00 0x01 0xa2 0x01 0x00 0x00 0x00 0x00 0x01 0xa3 0x01 0x00 0x00 0x01 0x00 0x01 0xa4 0x01 0x00 0x00 0x00 0x00 0x01 0xa5 0x01 0x00 0x00 0x00 0x00 0x01 0xa6 0x01 0x00 0x00 0x00 0x00 0x01 0xa7 0x01 0x00 0x00 0x01 0x00 0x01 0xa8 0x01 0x00 0x00 0x00 0x00 0x00 0xa9 0x01 0x00 0x00 0x00 0x00 0x01 0xaa 0x01 0x00 0x00 0x00 0x00 0x01 0xab 0x01 0x00 0x00 0x00 0x00 0x01 0xac 0x01 0x00 0x00 0x00 0x00 0x01 0xad 0x01 0x00 0x00 0x01 0x00 0x01 0xae 0x01 0x00 0x00 0x01 0x00 0x01 0xaf 0x01 0x00 0x00 0x01 0x00 0x01 0xb0 0x01 0x00 0x00 0x01 0x00 0x01 0xb1 0x01 0x00 0x00 0x01 0x00 0x00 0xb2 0x01 0x00 0x00 0x01 0x00 0x00 0xb3 0x01 0x00 0x00 0x01 0x00 0x00 0xb4 0x01 0x00 0x00 0x01 0x00 0x00 0xb5 0x01 0x00 0x00 0x01 0x00 0x00 0xb6 0x01 0x00 0x00 0x01 0x00 0x00 0xb7 0x01 0x00 0x00 0x01 0x00 0x00 0xb8 0x01 0x00 0x00 0x01 0x00 0x00 0xb9 0x01 0x00 0x00 0x01 0x00 0x00 0xba 0x00 0x00 0x00 0x01 0x00 0x01 0xbb 0x00 0x00 0x00 0x01 0x00 0x01 0xbc 0x00 0x00 0x00 0x01 0x00 0x00 0xbd 0x00 0x00 0x00 0x01 0x00 0x00 0xbe 0x00 0x00 0x00 0x01 0x00 0x00 0xbf 0x00 0x00 0x00 0x01 0x00 0x00 0xc0 0x00 0x00 0x00 0x01 0x00 0x00 0xc1 0x00 0x00 0x00 0x01 0x00 0x00 0xc2 0x00 0x00 0x00 0x01 0x00 0x00 0xc3 0x00 0x00 0x00 0x01 0x00 0x00 0xc4 0x00 0x00 0x00 0x01 0x00 0x00 0xc5 0x00 0x00 0x00 0x01 0x00 0x00 0xc6 0x00 0x00 0x00 0x01 0x00 0x00 0xc7 0x00 0x00 0x00 0x01 0x00 0x00 0xc8 0x00 0x00 0x00 0x01 0x00 0x00 0xc9 0x00 0x00 0x00 0x01 0x00 0x00 0xca 0x00 0x00 0x00 0x01 0x00 0x00 0xcb 0x00 0x00 0x00 0x01 0x00 0x00 0xcc 0x00 0x00 0x00 0x01 0x00 0x00 0xcd 0x00 0x00 0x00 0x01 0x00 0x00 0xce 0x00 0x00 0x00 0x01 0x00 0x00 0xcf 0x00 0x00 0x00 0x01 0x00 0x00 0xd0 0x00 0x00 0x00 0x01 0x00 0x00 0xd1 0x00 0x00 0x00 0x01 0x00 0x00 0xd2 0x00 0x00 0x00 0x01 0x00 0x00 0xd3 0x00 0x00 0x00 0x01 0x00 0x00 0xd4 0x00 0x00 0x00 0x01 0x00 0x00 0xd5 0x00 0x00 0x00 0x01 0x00 0x00 0xd6 0x00 0x00 0x00 0x01 0x00 0x00 0xd7 0x00 0x00 0x00 0x01 0x00 0x00 0xd8 0x00 0x00 0x00 0x01 0x00 0x00 0xd9 0x00 0x00 0x00 0x01 0x00 0x00 0xda 0x00 0x00 0x00 0x01 0x00 0x00 0xdb 0x00 0x00 0x00 0x01 0x00 0x00 0xdc 0x00 0x00 0x00 0x01 0x00 0x00 0xdd 0x00 0x00 0x00 0x01 0x00 0x00>;
		};
	};

	fragment@27 {
		target = <0xffffffff>;

		__overlay__ {
			interrupt-parent = <0xffffffff>;
			interrupts = <0x04 0x08>;
			status = "okay";
		};
	};

	fragment@28 {
		target = <0xffffffff>;

		__overlay__ {
			interrupt-parent = <0xffffffff>;
			interrupts = <0x06 0x08>;
			status = "okay";
		};
	};

	fragment@29 {
		target = <0xffffffff>;

		__overlay__ {
			interrupt-parent = <0xffffffff>;
			interrupts = <0x09 0x02>;
			status = "okay";
		};
	};

	fragment@30 {
		target = <0xffffffff>;

		__overlay__ {
			interrupt-parent = <0xffffffff>;
			interrupts = <0x53 0x01>;
			status = "okay";
		};
	};

	fragment@31 {
		target = <0xffffffff>;

		__overlay__ {
			cd-gpios = <0xffffffff 0x09 0x00>;
		};
	};

	fragment@32 {
		target = <0xffffffff>;

		__overlay__ {
			compatible = "mediatek,md1_sim1_hot_plug_eint-eint";
			interrupts = <0x00 0x08>;
			debounce = <0x00 0x2710>;
			dedicated = <0x00 0x00>;
			src_pin = <0x00 0x01>;
			sockettype = <0x00 0x00>;
			status = "okay";
		};
	};

	fragment@33 {
		target = <0xffffffff>;

		__overlay__ {
			compatible = "mediatek,md1_sim2_hot_plug_eint-eint";
			interrupts = <0x01 0x08>;
			debounce = <0x01 0x2710>;
			dedicated = <0x01 0x00>;
			src_pin = <0x01 0x02>;
			sockettype = <0x01 0x00>;
			status = "okay";
		};
	};

	fragment@34 {
		target = <0xffffffff>;

		__overlay__ {
			mediatek,long-press-mode = <0x02>;

			home {
				linux,keycodes = <0x72>;
			};
		};
	};

	fragment@35 {
		target = <0xffffffff>;

		__overlay__ {
			mediatek,key-debounce = <0x400>;
			mediatek,sw-pwrkey = <0x74>;
			mediatek,hw-pwrkey = <0x08>;
			mediatek,sw-rstkey = <0x72>;
			mediatek,hw-rstkey = <0x11>;
			mediatek,use-extend-type = <0x00>;
			mediatek,hw-map-num = <0x48>;
			mediatek,hw-init-map = <0x00 0x73 0x00 0x00 0x00 0x00 0x00 0x00 0x00 0x00 0x00 0x00 0x00 0x00 0x00 0x00 0x00 0x00 0x00 0x00 0x00 0x00 0x00 0x00 0x00 0x00 0x00 0x00 0x00 0x00 0x00 0x00 0x00 0x00 0x00 0x00 0x00 0x00 0x00 0x00 0x00 0x00 0x00 0x00 0x00 0x00 0x00 0x00 0x00 0x00 0x00 0x00 0x00 0x00 0x00 0x00 0x00 0x00 0x00 0x00 0x00 0x00 0x00 0x00 0x00 0x00 0x00 0x00 0x00 0x00 0x00 0x00>;
			mediatek,pwrkey-eint-gpio = <0x00>;
			mediatek,pwkey-gpio-din = <0x00>;
			mediatek,hw-dl-key0 = <0x11>;
			mediatek,hw-dl-key1 = <0x00>;
			mediatek,hw-dl-key2 = <0x08>;
			mediatek,hw-recovery-key = <0x11>;
			mediatek,hw-factory-key = <0x00>;
			status = "okay";
		};
	};

	fragment@36 {
		target = <0xffffffff>;

		__overlay__ {
			#address-cells = <0x01>;
			#size-cells = <0x00>;
			status = "okay";

			s2mpb03_pmic@56 {
				compatible = "samsung,s2mpb03pmic";
				reg = <0x56>;
				s2mpb03,wakeup;
				phandle = <0x97>;

				regulators {

					s2mpb03-ldo1 {
						regulator-name = "CAM0_s2mpb03-l1";
						regulator-min-microvolt = <0x100590>;
						regulator-max-microvolt = <0x10c8e0>;
						phandle = <0x78>;
					};

					s2mpb03-ldo2 {
						regulator-name = "CAM0_s2mpb03-l2";
						regulator-min-microvolt = <0x10c8e0>;
						regulator-max-microvolt = <0x124f80>;
						phandle = <0x7c>;
					};

					s2mpb03-ldo3 {
						regulator-name = "CAM0_s2mpb03-l3";
						regulator-min-microvolt = <0x1b7740>;
						regulator-max-microvolt = <0x1b7740>;
						phandle = <0x7a>;
					};

					s2mpb03-ldo4 {
						regulator-name = "CAM0_s2mpb03-l4";
						regulator-min-microvolt = <0x124f80>;
						regulator-max-microvolt = <0x124f80>;
						phandle = <0x7e>;
					};

					s2mpb03-ldo5 {
						regulator-name = "CAM0_s2mpb03-l5";
						regulator-min-microvolt = <0x2ab980>;
						regulator-max-microvolt = <0x2ab980>;
						phandle = <0x79>;
					};

					s2mpb03-ldo6 {
						regulator-name = "CAM0_s2mpb03-l6";
						regulator-min-microvolt = <0x2ab980>;
						regulator-max-microvolt = <0x2ab980>;
						phandle = <0x7d>;
					};

					s2mpb03-ldo7 {
						regulator-name = "CAM0_s2mpb03-l7";
						regulator-min-microvolt = <0x2ab980>;
						regulator-max-microvolt = <0x2ab980>;
						phandle = <0x7b>;
					};
				};
			};
		};
	};

	fragment@37 {
		target = <0xffffffff>;

		__overlay__ {

			gpio_i2c_0_sda {

				gpio_i2c_0_sda_default {
					phandle = <0x98>;

					pins_cmd_dat {
						pinmux = <0x6800>;
						bias-disable;
						input-enable;
						drive-strength = <0x02>;
					};
				};
			};
		};
	};

	fragment@38 {
		target = <0xffffffff>;

		__overlay__ {

			gpio_i2c_0_scl {

				gpio_i2c_0_scl_default {
					phandle = <0x99>;

					pins_cmd_dat {
						pinmux = <0x6700>;
						bias-disable;
						input-enable;
						drive-strength = <0x02>;
					};
				};
			};
		};
	};

	fragment@39 {
		target = <0xffffffff>;

		__overlay__ {

			gfspi_drdypin_active {
				phandle = <0x0a>;

				pins_cmd_dat {
					pinmux = <0x1100>;
					bias-disable;
					drive-strength = <0x01>;
				};
			};

			gfspi_drdypin_suspend {
				phandle = <0x09>;

				pins_cmd_dat {
					pinmux = <0x1100>;
					bias-pull-down;
					drive-strength = <0x01>;
				};
			};
		};
	};

	fragment@40 {
		target = <0xffffffff>;

		__overlay__ {

			gfspi_rstpin {
				phandle = <0x08>;

				pins_cmd_dat {
					pinmux = <0x6500>;
					bias-pull-down;
					drive-strength = <0x01>;
				};
			};
		};
	};

	fragment@41 {
		target = <0xffffffff>;

		__overlay__ {

			gfspi_ldopin {
				phandle = <0x07>;

				pins_cmd_dat {
					pinmux = <0x6600>;
					bias-pull-down;
				};
			};
		};
	};

	fragment@42 {
		target = <0xffffffff>;

		__overlay__ {

			set_miso {
				phandle = <0x0b>;

				pins_cmd_dat {
					pinmux = <0x2d01>;
					drive-strength = <0x04>;
				};
			};

			set_cs {
				phandle = <0x0c>;

				pins_cmd_dat {
					pinmux = <0x2b01>;
					drive-strength = <0x04>;
				};
			};

			set_mosi {
				phandle = <0x0d>;

				pins_cmd_dat {
					pinmux = <0x2c01>;
					drive-strength = <0x04>;
				};
			};

			set_clk {
				phandle = <0x0e>;

				pins_cmd_dat {
					pinmux = <0x2a01>;
					drive-strength = <0x04>;
				};
			};

			clr_miso {
				phandle = <0x0f>;

				pins_cmd_dat {
					pinmux = <0x2d00>;
					slew-rate = <0x00>;
					bias-pull-down;
					input-enable;
					drive-strength = <0x01>;
				};
			};

			clr_cs {
				phandle = <0x10>;

				pins_cmd_dat {
					pinmux = <0x2b00>;
					slew-rate = <0x00>;
					bias-pull-down;
					output-low;
					drive-strength = <0x01>;
				};
			};

			clr_mosi {
				phandle = <0x11>;

				pins_cmd_dat {
					pinmux = <0x2c00>;
					slew-rate = <0x00>;
					bias-pull-down;
					output-low;
					drive-strength = <0x01>;
				};
			};

			clr_clk {
				phandle = <0x12>;

				pins_cmd_dat {
					pinmux = <0x2a00>;
					slew-rate = <0x00>;
					bias-pull-down;
					output-low;
					drive-strength = <0x01>;
				};
			};
		};
	};

	fragment@43 {
		target = <0xffffffff>;

		__overlay__ {
			status = "okay";

			sm5461@63 {
				compatible = "siliconmitus,sm5461";
				reg = <0x63>;
				sm5461,freq = <0x02>;
				sm5461,r_ttl = <0x7ef40>;
				sm5461,topoff = <0x17c>;
				sm5461,en_vbatreg = <0x01>;
				sm5461,single_mode = <0x01>;
				phandle = <0x9a>;
			};
		};
	};

	fragment@44 {
		target = <0xffffffff>;

		__overlay__ {

			if_pmic_irq {
				phandle = <0x43>;

				pins_cmd_dat {
					pinmux = <0x700>;
					slew-rate = <0x01>;
					bias-disable;
				};
			};

			usbpd_irq {
				phandle = <0x44>;

				pins_cmd_dat {
					pinmux = <0x800>;
					slew-rate = <0x01>;
					bias-disable;
				};
			};
		};
	};

	fragment@45 {
		target = <0xffffffff>;

		__overlay__ {
			#address-cells = <0x01>;
			#size-cells = <0x00>;
			status = "okay";
			clock-frequency = <0x61a80>;

			sm5714@49 {
				status = "okay";
				compatible = "siliconmitus,sm5714mfd";
				reg = <0x49>;
				pinctrl-names = "default";
				pinctrl-0 = <0x43>;
				sm5714,irq-gpio = <0xffffffff 0x07 0x00>;
				sm5714,wakeup;
			};
		};
	};

	fragment@46 {
		target = <0xffffffff>;

		__overlay__ {
			i2c-gpio,delay-us = <0x05>;
			#address-cells = <0x01>;
			#size-cells = <0x00>;
			status = "okay";
			clock-frequency = <0x61a80>;

			usbpd-sm5714@33 {
				status = "okay";
				compatible = "sm5714-usbpd";
				reg = <0x33>;
				pinctrl-names = "default";
				pinctrl-0 = <0x44>;
				usbpd,usbpd_int = <0xffffffff 0x08 0x00>;
				support_pd_role_swap;

				pdic-manager {
					pdic,max_power = <0x1388>;
					pdic_op_power = <0x9c4>;
					pdic_max_voltage = <0x1770>;
					pdic_max_current = <0x7d0>;
					pdic,min_current = <0x1f4>;
					pdic,giveback = <0x00>;
					pdic,usb_com_capable = <0x01>;
					pdic,no_usb_suspend = <0x01>;
					source,max_voltage = <0x1388>;
					source,min_voltage = <0xfa0>;
					source,max_power = <0x9c4>;
				};
			};
		};
	};

	fragment@47 {
		target = <0xffffffff>;

		__overlay__ {

			sec-mst,mst-pwr-gpio {
				phandle = <0x01>;

				pins_cmd_dat {
					pinmux = <0x400>;
					bias-pull-down;
					output-low;
				};
			};
		};
	};

	fragment@48 {
		target = <0xffffffff>;

		__overlay__ {
			regulator-min-microvolt = <0x2dc6c0>;
			regulator-max-microvolt = <0x2dc6c0>;
		};
	};

	fragment@49 {
		target = <0xffffffff>;

		__overlay__ {
			regulator-min-microvolt = <0x2932e0>;
			regulator-max-microvolt = <0x2c4020>;
		};
	};

	fragment@50 {
		target = <0xffffffff>;

		__overlay__ {
			regulator-min-microvolt = <0x2ab980>;
			regulator-max-microvolt = <0x2ab980>;
		};
	};

	fragment@51 {
		target = <0xffffffff>;

		__overlay__ {

			ldo_gpio4 {
				phandle = <0x02>;

				pins_cmd_dat {
					pinmux = <0x6900>;
					bias-disable;
					output-high;
				};
			};
		};
	};

	fragment@52 {
		target = <0xffffffff>;

		__overlay__ {

			ldo_gpio1 {
				phandle = <0x03>;

				pins_cmd_dat {
					pinmux = <0x9e00>;
					bias-disable;
					output-high;
				};
			};
		};
	};

	fragment@53 {
		target = <0xffffffff>;

		__overlay__ {

			ldo_gpio2 {
				phandle = <0x04>;

				pins_cmd_dat {
					pinmux = <0x1500>;
					bias-disable;
					output-high;
				};
			};
		};
	};

	fragment@54 {
		target = <0xffffffff>;

		__overlay__ {

			ldo_gpio3 {
				phandle = <0x05>;

				pins_cmd_dat {
					pinmux = <0x9800>;
					bias-disable;
					output-high;
				};
			};
		};
	};

	fragment@55 {
		target = <0xffffffff>;

		__overlay__ {

			ldo_gpio0 {
				phandle = <0x06>;

				pins_cmd_dat {
					pinmux = <0x1300>;
					bias-disable;
					output-high;
				};
			};
		};
	};

	fragment@56 {
		target = <0xffffffff>;

		__overlay__ {

			tsp_int {
				phandle = <0x45>;

				pins_cmd_dat {
					pinmux = <0xa00>;
					slew-rate = <0x00>;
					bias-disable;
				};
			};
		};
	};

	fragment@57 {
		target = <0xffffffff>;

		__overlay__ {
			#address-cells = <0x01>;
			#size-cells = <0x00>;
			status = "okay";
			clock-frequency = <0x61a80>;

			touchscreen@20 {
				status = "ok";
				compatible = "zinitix,zt_ts_device";
				reg = <0x20>;
				pinctrl-names = "on_state\0off_state";
				pinctrl-0 = <0x45>;
				pinctrl-1 = <0x45>;
				tsp_avdd_ldo-supply = <0x46>;
				sec,irq_gpio = <0xffffffff 0x0a 0x00>;
				sec,max_coords = <0x439 0x925>;
				zinitix,mis_cal_check;
				enable_settings_aot;
				support_ear_detect_mode;
				support_dex_mode;
				support_open_short_test;
				sec,enable_sysinput_enabled;
				not_support_io_ldo;
				sec,bitmask_unload = <0xff00 0x4200>;
				sec,tclm_level = <0x02>;
				sec,afe_base = <0x06>;
				zinitix,chip_name = "ZT7650M";
				sec,firmware_name = "zt7650m_a15.bin";
				sec,bringup = <0x00>;
				phandle = <0x9b>;
			};
		};
	};

	fragment@58 {
		target = <0xffffffff>;

		__overlay__ {

			snvm_i2c_on {
				phandle = <0x48>;

				pins_cmd_dat {
					pinmux = <0x8c01 0x8d01>;
					bias-disable;
				};
			};

			snvm_i2c_off {
				phandle = <0x47>;

				pins_cmd_dat {
					pinmux = <0x8c00 0x8d00>;
					input-enable;
					bias-pull-down;
				};
			};
		};
	};

	fragment@59 {
		target = <0xffffffff>;

		__overlay__ {
			clock-frequency = <0x61a80>;
			status = "okay";
			pinctrl-names = "default\0nvm_on\0nvm_off";
			pinctrl-0 = <0x47>;
			pinctrl-1 = <0x48>;
			pinctrl-2 = <0x47>;

			k250a@23 {
				compatible = "sec_k250a";
				1p8_pvdd-supply = <0x49>;
				reg = <0x23>;
			};
		};
	};

	fragment@60 {
		target = <0xffffffff>;

		__overlay__ {

			disp-rst-default {
				samsung,pins = "gpio85";
				samsung,pin-function = <0x01>;
				samsung,pin-pud = <0x00>;
				samsung,pin-con-pdn = <0x03>;
				samsung,pin-pud-pdn = <0x00>;
				phandle = <0x1a>;
			};
		};
	};

	fragment@61 {
		target = <0xffffffff>;

		__overlay__ {

			disp_det_default {
				phandle = <0x1b>;

				pins_cmd_dat {
					pinmux = <0x600>;
					bias-pull-down;
					input-enable;
				};
			};
		};
	};

	fragment@62 {
		target = <0xffffffff>;

		__overlay__ {

			conn_det_default {
				samsung,pins = "gpio35";
				samsung,pin-funciton = <0x00>;
				samsung,pin-pud = <0x00>;
				samsung,pin-con-pdn = <0x02>;
				samsung,pin-pud-pdn = <0x00>;
				phandle = <0x1c>;
			};
		};
	};

	fragment@63 {
		target = <0xffffffff>;

		__overlay__ {

			pcd_default {
				phandle = <0x9c>;

				pins_cmd_dat {
					pinmux = <0xe00>;
					bias-pull-down;
					input-enable;
				};
			};
		};
	};

	fragment@64 {
		target = <0xffffffff>;

		__overlay__ {

			grip-i2c-sda {
				phandle = <0x13>;

				pins_cmd_dat {
					pinmux = <0x6800>;
					bias-disable;
					input-enable;
					drive-strength = <0x02>;
				};
			};

			grip-i2c-scl {
				phandle = <0x14>;

				pins_cmd_dat {
					pinmux = <0x6700>;
					bias-disable;
					input-enable;
					drive-strength = <0x02>;
				};
			};
		};
	};

	fragment@65 {
		target = <0xffffffff>;

		__overlay__ {

			grip-int {
				phandle = <0x15>;

				pins_cmd_dat {
					pinmux = <0xc00>;
					bias-disable;
					input-enable;
					drive-strength = <0x02>;
				};
			};
		};
	};

	fragment@66 {
		target = <0xffffffff>;

		__overlay__ {
		};
	};

	fragment@67 {
		target = <0xffffffff>;

		__overlay__ {

			grip-ldo-en {
				phandle = <0x16>;

				pins_cmd_dat {
					pinmux = <0x5400>;
					bias-pull-down;
					input-enable;
					drive-strength = <0x02>;
				};
			};
		};
	};

	fragment@68 {
		target = <0xffffffff>;

		__overlay__ {

			ts_int_active {
				phandle = <0x4a>;

				pins_cmd_dat {
					pinmux = <0xa00>;
					bias-disable;
					input-enable;
				};
			};

			ts_int_suspend {
				phandle = <0x4b>;

				pins_cmd_dat {
					pinmux = <0xa00>;
					bias-disable;
					input-enable;
				};
			};
		};
	};

	fragment@69 {
		target = <0xffffffff>;

		__overlay__ {
			#address-cells = <0x01>;
			#size-cells = <0x00>;
			status = "okay";

			touchscreen@38 {
				status = "okay";
				compatible = "focaltech,fts";
				reg = <0x38>;
				pinctrl-names = "on_state\0off_state";
				pinctrl-0 = <0x4a>;
				pinctrl-1 = <0x4b>;
				tsp_avdd_ldo-supply = <0x46>;
				sec,irq_gpio = <0xffffffff 0x0a 0x02>;
				support_dex_mode;
				sec,enable_sysinput_enabled;
				support_open_short_test;
				not_support_io_ldo;
				support_ear_detect_mode;
				support_fod;
				support_fod_lp_mode;
				support_refresh_rate_mode;
				enable_settings_aot;
				sec_cmd,not_support_cmds = "refresh_rate_mode";
				sec,bitmask_unload = <0xff00 0x200>;
				sec,max_coords = <0x438 0x924>;
				sec,firmware_name = "ft3418_a15.bin";
				sec,bringup = <0x00>;
				phandle = <0x9d>;
			};
		};
	};

	fragment@70 {
		target = <0xffffffff>;

		__overlay__ {

			tsp_i2c_sda_default {
				phandle = <0x4c>;

				pins_cmd_dat {
					pinmux = <0x9101>;
					bias-pull-up = <0xce>;
				};
			};

			tsp_i2c_scl_default {
				phandle = <0x4d>;

				pins_cmd_dat {
					pinmux = <0x9001>;
					bias-pull-up = <0xce>;
				};
			};
		};
	};

	fragment@71 {
		target = <0xffffffff>;

		__overlay__ {
			pinctrl-names = "default";
			pinctrl-0 = <0x4c 0x4d>;
		};
	};

	fragment@72 {
		target = <0xffffffff>;

		__overlay__ {

			nfc_ven {
				phandle = <0x4f>;

				pins_cmd_dat {
					pinmux = <0x9c00>;
					output-low;
					bias-disable;
				};
			};

			ven_nc {
				phandle = <0x55>;

				pins_cmd_dat {
					pinmux = <0x9c00>;
					input-enable;
					bias-pull-down;
				};
			};
		};
	};

	fragment@73 {
		target = <0xffffffff>;

		__overlay__ {

			nfc_firm {
				phandle = <0x50>;

				pins_cmd_dat {
					pinmux = <0x9b00>;
					output-low;
					bias-disable;
				};
			};

			firm_nc {
				phandle = <0x56>;

				pins_cmd_dat {
					pinmux = <0x9b00>;
					input-enable;
					bias-pull-down;
				};
			};
		};
	};

	fragment@74 {
		target = <0xffffffff>;

		__overlay__ {

			nfc_clk_req {
				phandle = <0x51>;

				pins_cmd_dat {
					pinmux = <0x100>;
					input-enable;
					bias-pull-down;
				};
			};

			clk_req_nc {
				phandle = <0x57>;

				pins_cmd_dat {
					pinmux = <0x100>;
					input-enable;
					bias-pull-down;
				};
			};
		};
	};

	fragment@75 {
		target = <0xffffffff>;

		__overlay__ {

			nfc_irq {
				phandle = <0x52>;

				pins_cmd_dat {
					pinmux = <0x300>;
					input-enable;
					bias-pull-down;
				};
			};

			irq_nc {
				phandle = <0x58>;

				pins_cmd_dat {
					pinmux = <0x300>;
					input-enable;
					bias-pull-down;
				};
			};
		};
	};

	fragment@76 {
		target = <0xffffffff>;

		__overlay__ {

			nfc_i2c_off {
				phandle = <0x59>;

				pins_cmd_dat {
					pinmux = <0x8e00 0x8f00>;
					input-enable;
					bias-pull-down;
				};
			};

			nfc_i2c_on {
				phandle = <0x53>;

				pins_cmd_dat {
					pinmux = <0x8e01 0x8f01>;
					bias-pull-up;
				};
			};
		};
	};

	fragment@77 {
		target = <0xffffffff>;

		__overlay__ {

			nfc_check {
				phandle = <0x54>;

				pins_cmd_dat {
					pinmux = <0x9a00>;
					input-enable;
					bias-disable;
				};
			};
		};
	};

	fragment@78 {
		target = <0xffffffff>;

		__overlay__ {
			status = "ok";
			clock-frequency = <0x61a80>;
			mediatek,use-open-drain;

			pn547@2B {
				compatible = "pn547";
				reg = <0x2b>;
				interrupt-parent = <0xffffffff>;
				interrupts = <0x03 0x01 0x03 0x00>;
				pn547,irq-gpio = <0xffffffff 0x03 0x00>;
				pn547,ven-gpio = <0xffffffff 0x9c 0x00>;
				pn547,firm-gpio = <0xffffffff 0x9b 0x00>;
				pn547,clk_req-gpio = <0xffffffff 0x01 0x00>;
				pn547,clk_req_wake;
				nfc_pvdd-supply = <0x4e>;
				pn547,ldo_control;
				pn547,nfc-det-gpio = <0xffffffff 0x9a 0x00>;
				pn547,ap_vendor = "mtk";
				pinctrl-names = "default\0nfc_nc\0i2c_off";
				pinctrl-0 = <0x4f 0x50 0x51 0x52 0x53 0x54>;
				pinctrl-1 = <0x55 0x56 0x57 0x58 0x59>;
				pinctrl-2 = <0x59>;
			};
		};
	};

	fragment@79 {
		target = <0xffffffff>;

		__overlay__ {

			rt5133@18 {
				status = "disabled";
				phandle = <0x9e>;
			};
		};
	};

	fragment@80 {
		target = <0xffffffff>;

		__overlay__ {
			status = "okay";
			id = <0x12>;
			clock-frequency = <0x61a80>;
			#address-cells = <0x01>;
			#size-cells = <0x00>;

			aw88230_amp@34 {
				compatible = "awinic,aw882xx_smartpa";
				#sound-dai-cells = <0x00>;
				reg = <0x34>;
				irq-gpio = <0xffffffff 0x0b 0x00>;
				sound-channel = <0x00>;
				aw-cali-mode = "none";
				status = "okay";
				phandle = <0x5a>;
			};
		};
	};

	fragment@81 {
		target = <0xffffffff>;

		__overlay__ {

			pins_cmd_dat {
				pinmux = <0xab00>;
				input-enable;
				bias-disable;
			};
		};
	};

	fragment@82 {
		target = <0xffffffff>;

		__overlay__ {
			mediatek,spk-i2s = <0x03 0x00>;

			mediatek,speaker-codec {
				sound-dai = <0x5a>;
			};
		};
	};

	fragment@83 {
		target = <0xffffffff>;

		__overlay__ {
			scp_spk_process_enable = <0x00 0x04 0x0f 0x13>;
			status = "disabled";
		};
	};

	fragment@84 {
		target = <0xffffffff>;

		__overlay__ {
			headset-vol-threshold = <0x00 0x27e 0x27f 0x7d0 0xa28>;
			headset-four-key-threshold = <0x00 0xa5 0xc5 0x118 0x226>;
		};
	};

	fragment@85 {
		target = <0xffffffff>;

		__overlay__ {

			panel@0 {
				compatible = "samsung,mcd-panel-samsung-drv";
			};
		};
	};

	fragment@86 {
		target = <0xffffffff>;

		__overlay__ {
			sec,wb-enable;
			sec,wb-up-threshold-block = <0xc00>;
			sec,wb-up-threshold-rqs = <0x1e>;
			sec,wb-down-threshold-block = <0x600>;
			sec,wb-down-threshold-rqs = <0x19>;
			sec,wb-disable-threshold-lt = <0x07>;
			sec,wb-on-delay-ms = <0x5c>;
			sec,wb-off-delay-ms = <0x1194>;
		};
	};

	fragment@87 {
		target = <0xffffffff>;

		__overlay__ {

			camera0_mclk_2mA@gpio126 {
				phandle = <0x5d>;

				pins_cmd_dat {
					pinmux = <0x7e01>;
					drive-strength = <0x00>;
				};
			};

			camera0_mclk_4mA@gpio126 {
				phandle = <0x5e>;

				pins_cmd_dat {
					pinmux = <0x7e01>;
					drive-strength = <0x01>;
				};
			};

			camera0_mclk_6mA@gpio126 {
				phandle = <0x5f>;

				pins_cmd_dat {
					pinmux = <0x7e01>;
					drive-strength = <0x02>;
				};
			};

			camera0_mclk_8mA@gpio126 {
				phandle = <0x60>;

				pins_cmd_dat {
					pinmux = <0x7e01>;
					drive-strength = <0x03>;
				};
			};

			camera0_mclk_gpio_mode@gpio126 {
				phandle = <0x5c>;

				pins_cmd_dat {
					pinmux = <0x7e00>;
					drive-strength = <0x03>;
				};
			};

			camera0_rst_output_low@gpio16 {
				phandle = <0x61>;

				pins_cmd_dat {
					pinmux = <0x1000>;
					output-low;
				};
			};

			camera0_rst_output_high@gpio16 {
				phandle = <0x62>;

				pins_cmd_dat {
					pinmux = <0x1000>;
					output-high;
				};
			};

			camera_main_i2c_scl_on@gpio146 {
				phandle = <0x9f>;

				pins_cmd_dat {
					pinmux = <0x9201>;
					bias-disable;
				};
			};

			camera_main_i2c_sda_on@gpio147 {
				phandle = <0xa0>;

				pins_cmd_dat {
					pinmux = <0x9301>;
					bias-disable;
				};
			};

			camera_main_i2c_scl_off@gpio146 {
				phandle = <0xa1>;

				pins_cmd_dat {
					pinmux = <0x9200>;
					bias-disable;
				};
			};

			camera_main_i2c_sda_off@gpio147 {
				phandle = <0xa2>;

				pins_cmd_dat {
					pinmux = <0x9300>;
					bias-disable;
				};
			};

			camera1_mclk_2mA@gpio129 {
				phandle = <0x64>;

				pins_cmd_dat {
					pinmux = <0x8101>;
					drive-strength = <0x00>;
				};
			};

			camera1_mclk_4mA@gpio129 {
				phandle = <0x65>;

				pins_cmd_dat {
					pinmux = <0x8101>;
					drive-strength = <0x01>;
				};
			};

			camera1_mclk_6mA@gpio129 {
				phandle = <0x66>;

				pins_cmd_dat {
					pinmux = <0x8101>;
					drive-strength = <0x02>;
				};
			};

			camera1_mclk_8mA@gpio129 {
				phandle = <0x67>;

				pins_cmd_dat {
					pinmux = <0x8101>;
					drive-strength = <0x03>;
				};
			};

			camera1_mclk_gpio_mode@gpio129 {
				phandle = <0x63>;

				pins_cmd_dat {
					pinmux = <0x8100>;
					drive-strength = <0x01>;
				};
			};

			camera1_rst_output_low@gpio15 {
				phandle = <0x68>;

				pins_cmd_dat {
					pinmux = <0xf00>;
					output-low;
				};
			};

			camera1_rst_output_high@gpio15 {
				phandle = <0x69>;

				pins_cmd_dat {
					pinmux = <0xf00>;
					output-high;
				};
			};

			camera_sub_i2c_scl_on@gpio138 {
				phandle = <0xa3>;

				pins_cmd_dat {
					pinmux = <0x8a01>;
					bias-pull-up;
				};
			};

			camera_sub_i2c_sda_on@gpio139 {
				phandle = <0xa4>;

				pins_cmd_dat {
					pinmux = <0x8b01>;
					bias-pull-up;
				};
			};

			camera_sub_i2c_scl_off@gpio138 {
				phandle = <0xa5>;

				pins_cmd_dat {
					pinmux = <0x8a00>;
					bias-pull-down;
				};
			};

			camera_sub_i2c_sda_off@gpio139 {
				phandle = <0xa6>;

				pins_cmd_dat {
					pinmux = <0x8b00>;
					bias-pull-down;
				};
			};

			camera2_mclk_2mA@gpio127 {
				phandle = <0x6b>;

				pins_cmd_dat {
					pinmux = <0x7f01>;
					drive-strength = <0x00>;
				};
			};

			camera2_mclk_4mA@gpio127 {
				phandle = <0x6c>;

				pins_cmd_dat {
					pinmux = <0x7f01>;
					drive-strength = <0x01>;
				};
			};

			camera2_mclk_6mA@gpio127 {
				phandle = <0x6d>;

				pins_cmd_dat {
					pinmux = <0x7f01>;
					drive-strength = <0x02>;
				};
			};

			camera2_mclk_8mA@gpio127 {
				phandle = <0x6e>;

				pins_cmd_dat {
					pinmux = <0x7f01>;
					drive-strength = <0x03>;
				};
			};

			camera2_mclk_gpio_mode@gpio127 {
				phandle = <0x6a>;

				pins_cmd_dat {
					pinmux = <0x7f00>;
					drive-strength = <0x01>;
				};
			};

			camera2_rst_output_low@gpio18 {
				phandle = <0x6f>;

				pins_cmd_dat {
					pinmux = <0x1200>;
					output-low;
				};
			};

			camera2_rst_output_high@gpio18 {
				phandle = <0x70>;

				pins_cmd_dat {
					pinmux = <0x1200>;
					output-high;
				};
			};

			camera_main_two_i2c_scl_on@gpio134 {
				phandle = <0xa7>;

				pins_cmd_dat {
					pinmux = <0x8601>;
					bias-pull-up;
				};
			};

			camera_main_two_i2c_sda_on@gpio135 {
				phandle = <0xa8>;

				pins_cmd_dat {
					pinmux = <0x8701>;
					bias-pull-up;
				};
			};

			camera_main_two_i2c_scl_off@gpio134 {
				phandle = <0xa9>;

				pins_cmd_dat {
					pinmux = <0x8600>;
					bias-pull-down;
				};
			};

			camera_main_two_i2c_sda_off@gpio135 {
				phandle = <0xaa>;

				pins_cmd_dat {
					pinmux = <0x8700>;
					bias-pull-down;
				};
			};

			camera3_mclk_2mA@gpio128 {
				phandle = <0x72>;

				pins_cmd_dat {
					pinmux = <0x8001>;
					drive-strength = <0x00>;
				};
			};

			camera3_mclk_4mA@gpio128 {
				phandle = <0x73>;

				pins_cmd_dat {
					pinmux = <0x8001>;
					drive-strength = <0x01>;
				};
			};

			camera3_mclk_6mA@gpio128 {
				phandle = <0x74>;

				pins_cmd_dat {
					pinmux = <0x8001>;
					drive-strength = <0x02>;
				};
			};

			camera3_mclk_8mA@gpio128 {
				phandle = <0x75>;

				pins_cmd_dat {
					pinmux = <0x8001>;
					drive-strength = <0x03>;
				};
			};

			camera3_mclk_gpio_mode@gpio128 {
				phandle = <0x71>;

				pins_cmd_dat {
					pinmux = <0x8000>;
					drive-strength = <0x03>;
				};
			};

			camera3_rst_output_low@gpio22 {
				phandle = <0x76>;

				pins_cmd_dat {
					pinmux = <0x1600>;
					output-low;
				};
			};

			camera3_rst_output_high@gpio22 {
				phandle = <0x77>;

				pins_cmd_dat {
					pinmux = <0x1600>;
					output-high;
				};
			};

			camera_main_four_i2c_scl_on@gpio134 {
				phandle = <0xab>;

				pins_cmd_dat {
					pinmux = <0x8601>;
					bias-pull-up;
				};
			};

			camera_main_four_i2c_sda_on@gpio135 {
				phandle = <0xac>;

				pins_cmd_dat {
					pinmux = <0x8701>;
					bias-pull-up;
				};
			};

			camera_main_four_i2c_scl_off@gpio134 {
				phandle = <0xad>;

				pins_cmd_dat {
					pinmux = <0x8600>;
					bias-pull-down;
				};
			};

			camera_main_four_i2c_sda_off@gpio135 {
				phandle = <0xae>;

				pins_cmd_dat {
					pinmux = <0x8700>;
					bias-pull-down;
				};
			};

			camera_i2c2_pull_up_2k {
				phandle = <0x7f>;

				pins_bus {
					pinmux = <0x8701 0x8601>;
					bias-pull-up = <0xcd>;
				};
			};

			camdefault {
				phandle = <0x5b>;
			};
		};
	};

	fragment@88 {
		target = <0xffffffff>;

		__overlay__ {
			pinctrl-names = "default\0cam0_mclk_off\0cam0_mclk_2mA\0cam0_mclk_4mA\0cam0_mclk_6mA\0cam0_mclk_8mA\0cam0_rst0\0cam0_rst1\0cam1_mclk_off\0cam1_mclk_2mA\0cam1_mclk_4mA\0cam1_mclk_6mA\0cam1_mclk_8mA\0cam1_rst0\0cam1_rst1\0cam2_mclk_off\0cam2_mclk_2mA\0cam2_mclk_4mA\0cam2_mclk_6mA\0cam2_mclk_8mA\0cam2_rst0\0cam2_rst1\0cam3_mclk_off\0cam3_mclk_2mA\0cam3_mclk_4mA\0cam3_mclk_6mA\0cam3_mclk_8mA\0cam3_rst0\0cam3_rst1";
			pinctrl-0 = <0x5b>;
			pinctrl-1 = <0x5c>;
			pinctrl-2 = <0x5d>;
			pinctrl-3 = <0x5e>;
			pinctrl-4 = <0x5f>;
			pinctrl-5 = <0x60>;
			pinctrl-6 = <0x61>;
			pinctrl-7 = <0x62>;
			pinctrl-8 = <0x63>;
			pinctrl-9 = <0x64>;
			pinctrl-10 = <0x65>;
			pinctrl-11 = <0x66>;
			pinctrl-12 = <0x67>;
			pinctrl-13 = <0x68>;
			pinctrl-14 = <0x69>;
			pinctrl-15 = <0x6a>;
			pinctrl-16 = <0x6b>;
			pinctrl-17 = <0x6c>;
			pinctrl-18 = <0x6d>;
			pinctrl-19 = <0x6e>;
			pinctrl-20 = <0x6f>;
			pinctrl-21 = <0x70>;
			pinctrl-22 = <0x71>;
			pinctrl-23 = <0x72>;
			pinctrl-24 = <0x73>;
			pinctrl-25 = <0x74>;
			pinctrl-26 = <0x75>;
			pinctrl-27 = <0x76>;
			pinctrl-28 = <0x77>;
			cam0_vcamd-supply = <0x78>;
			cam0_vcama-supply = <0x79>;
			cam0_vcamio-supply = <0x7a>;
			cam0_vcamaf-supply = <0x7b>;
			cam1_vcamd-supply = <0x7c>;
			cam1_vcama-supply = <0x7d>;
			cam1_vcamio-supply = <0x7a>;
			cam1_vcamd1-supply = <0x7e>;
			cam2_vcamd-supply = <0x7e>;
			cam2_vcama-supply = <0x7d>;
			cam2_vcamio-supply = <0x7a>;
			cam3_vcama-supply = <0x7d>;
			cam3_vcamio-supply = <0x7a>;
			cam3_vcamd1-supply = <0x7e>;
			status = "okay";

			vendor {
				rear_sensor_id = <0x78>;
				front_sensor_id = <0x79>;
				rear2_sensor_id = <0xd2>;
				rear3_sensor_id = <0xd3>;
				use_dualcam_set_cal;
				use_module_check;
				check_final_cam_module;
				max_supported_camera = <0x04>;
				supported_cameraId = <0x00 0x01 0x32 0x36>;
				max_camera_num = <0x04>;

				camera_info0 {
					isp = <0x00>;
					cal_memory = <0x02>;
					read_version = <0x00>;
					core_voltage = <0x00>;
					upgrade = <0x00>;
					companion = <0x00>;
					ois = <0x00>;
					valid = <0x01>;
					dual_open = <0x00>;
					position = <0x00>;
					afcal_type = <0x14>;
					use_adaptive_mipi = <0x01>;
				};

				camera_info1 {
					isp = <0x00>;
					cal_memory = <0x02>;
					read_version = <0x00>;
					core_voltage = <0x00>;
					upgrade = <0x00>;
					companion = <0x00>;
					ois = <0x00>;
					valid = <0x01>;
					dual_open = <0x00>;
					position = <0x01>;
					use_adaptive_mipi = <0x01>;
				};

				camera_info2 {
					isp = <0x00>;
					cal_memory = <0x03>;
					read_version = <0x00>;
					core_voltage = <0x00>;
					upgrade = <0x00>;
					companion = <0x00>;
					ois = <0x00>;
					valid = <0x01>;
					dual_open = <0x00>;
					position = <0x02>;
					use_adaptive_mipi = <0x00>;
				};

				camera_info3 {
					isp = <0x00>;
					cal_memory = <0x02>;
					read_version = <0x00>;
					core_voltage = <0x00>;
					upgrade = <0x00>;
					companion = <0x00>;
					ois = <0x00>;
					valid = <0x01>;
					dual_open = <0x00>;
					position = <0x04>;
					use_adaptive_mipi = <0x00>;
				};
			};
		};
	};

	fragment@89 {
		target = <0xffffffff>;

		__overlay__ {
			status = "okay";
			#address-cells = <0x01>;
			#size-cells = <0x00>;
			clock-frequency = <0x61a80>;
			mediatek,use-open-drain;
			pinctrl-names = "default";
			pinctrl-0 = <0x7f>;

			camera_main_two@6C {
				compatible = "mediatek,camera_main_two";
				reg = <0x36>;
				status = "okay";
				phandle = <0xaf>;
			};

			camera_main_three@20 {
				compatible = "mediatek,camera_main_three";
				reg = <0x10>;
				status = "okay";
				phandle = <0xb0>;
			};

			camera_eeprom2@B6 {
				compatible = "mediatek,camera_eeprom";
				reg = <0x5b>;
				status = "okay";
				phandle = <0xb1>;
			};

			camera_eeprom3@A4 {
				compatible = "mediatek,camera_eeprom";
				reg = <0x52>;
				status = "okay";
				phandle = <0xb2>;
			};
		};
	};

	fragment@90 {
		target = <0xffffffff>;

		__overlay__ {
			status = "okay";
			#address-cells = <0x01>;
			#size-cells = <0x00>;
			clock-frequency = <0xf4240>;
			mediatek,use-open-drain;

			camera_sub@72 {
				compatible = "mediatek,camera_sub";
				reg = <0x39>;
				status = "okay";
				phandle = <0xb3>;
			};

			camera_eeprom1@A2 {
				compatible = "mediatek,camera_eeprom";
				reg = <0x51>;
				status = "okay";
				phandle = <0xb4>;
			};
		};
	};

	fragment@91 {
		target = <0xffffffff>;

		__overlay__ {
			status = "okay";
			#address-cells = <0x01>;
			#size-cells = <0x00>;
			clock-frequency = <0xf4240>;
			mediatek,use-open-drain;

			camera_main@AC {
				compatible = "mediatek,camera_main";
				reg = <0x56>;
				status = "okay";
				phandle = <0xb5>;
			};

			camera_eeprom0@A0 {
				compatible = "mediatek,camera_eeprom";
				reg = <0x50>;
				status = "okay";
				phandle = <0xb6>;
			};
		};
	};

	fragment@92 {
		target = <0xffffffff>;

		__overlay__ {

			sm5714@49 {

				sm5714-fled {
					status = "okay";
					compatible = "siliconmitus,sm5714-fled";
					flash-en-gpio = <0xffffffff 0x96 0x00>;
					torch-en-gpio = <0xffffffff 0x97 0x00>;
					flash-brightness = <0x0a>;
					preflash-brightness = <0x04>;
					torch-brightness = <0x04>;
					factory_current = <0x06>;
					flashlight_current = <0x00 0x01 0x02 0x05 0x07>;
					timeout = <0xff>;
				};
			};
		};
	};

	__symbols__ {
		smd = "/fragment@smd/__overlay__/samsung_mobile_device";
		vib_info = "/fragment@smd/__overlay__/samsung_mobile_device/vibrator_info";
		sm5714_charger = "/fragment@smd/__overlay__/samsung_mobile_device/sm5714-charger";
		sec_battery = "/fragment@smd/__overlay__/samsung_mobile_device/battery";
		sm5714_fuelgauge = "/fragment@smd/__overlay__/samsung_mobile_device/sm5714-fuelgauge";
		sec_wf_thermistor = "/fragment@smd/__overlay__/samsung_mobile_device/sec_thermistor@2";
		sec_ap_thermistor = "/fragment@smd/__overlay__/samsung_mobile_device/sec_thermistor@0";
		sec_pa_thermistor = "/fragment@smd/__overlay__/samsung_mobile_device/sec_thermistor@1";
		sec_mst = "/fragment@smd/__overlay__/samsung_mobile_device/sec-mst";
		fixed_regulator4 = "/fragment@smd/__overlay__/samsung_mobile_device/fixed_regulator@4";
		fixed_regulator1 = "/fragment@smd/__overlay__/samsung_mobile_device/fixed_regulator@1";
		fixed_regulator2 = "/fragment@smd/__overlay__/samsung_mobile_device/fixed_regulator@2";
		fixed_regulator3 = "/fragment@smd/__overlay__/samsung_mobile_device/fixed_regulator@3";
		fixed_regulator0 = "/fragment@smd/__overlay__/samsung_mobile_device/fixed_regulator@0";
		sec_battery_cable = "/fragment@smd/__overlay__/samsung_mobile_device/cable-info";
		sec_battery_wireless_power_info = "/fragment@smd/__overlay__/samsung_mobile_device/wireless-power-info";
		sw_i2c0 = "/fragment@model/__overlay__/i2c@30";
		sx9385 = "/fragment@model/__overlay__/i2c@30/sx9385-i2c@29";
		s6e8fc3_a15_panel_dsc_picture_parameter_set_default = "/fragment@panel_display_mode/__overlay__/s6e8fc3_a15_panel_dsc_picture_parameter_set_default";
		a15_panel_display_modes = "/fragment@panel_display_mode/__overlay__/a15_panel_display_modes";
		a15_panel_display_mode_1080x2340_90hs = "/fragment@panel_display_mode/__overlay__/a15_panel_display_modes/a15_panel_display_mode_1080x2340_90hs";
		a15_panel_display_mode_1080x2340_60hs = "/fragment@panel_display_mode/__overlay__/a15_panel_display_modes/a15_panel_display_mode_1080x2340_60hs";
		panel_drv_0 = "/fragment@panel_drv/__overlay__/panel_drv_0";
		s6e8fc3_a15_power_ctrl = "/fragment@panel_drv/__overlay__/panel_drv_0/s6e8fc3_a15_power_ctrl";
		fc3_a15_vci_on = "/fragment@panel_drv/__overlay__/panel_drv_0/s6e8fc3_a15_power_ctrl/actions/vci-on";
		fc3_a15_vdd3_on = "/fragment@panel_drv/__overlay__/panel_drv_0/s6e8fc3_a15_power_ctrl/actions/vdd3-on";
		fc3_a15_vci_off = "/fragment@panel_drv/__overlay__/panel_drv_0/s6e8fc3_a15_power_ctrl/actions/vci-off";
		fc3_a15_vdd3_off = "/fragment@panel_drv/__overlay__/panel_drv_0/s6e8fc3_a15_power_ctrl/actions/vdd3-off";
		fc3_a15_delay_1ms = "/fragment@panel_drv/__overlay__/panel_drv_0/s6e8fc3_a15_power_ctrl/actions/delay-1ms";
		fc3_a15_delay_10ms = "/fragment@panel_drv/__overlay__/panel_drv_0/s6e8fc3_a15_power_ctrl/actions/delay-10ms";
		fc3_a15_reset_high = "/fragment@panel_drv/__overlay__/panel_drv_0/s6e8fc3_a15_power_ctrl/actions/reset-high";
		fc3_a15_reset_low = "/fragment@panel_drv/__overlay__/panel_drv_0/s6e8fc3_a15_power_ctrl/actions/reset-low";
		s6e8fc3_a15_ap = "/fragment@panel_drv/__overlay__/panel_drv_0/s6e8fc3_a15_ap";
		s6e8fc3_a15 = "/fragment@panel_drv/__overlay__/panel_drv_0/panels/s6e8fc3_a15";
		disp_reset = "/fragment@panel_drv/__overlay__/panel_drv_0/gpios/disp-reset";
		disp_det = "/fragment@panel_drv/__overlay__/panel_drv_0/gpios/disp-det";
		conn_det = "/fragment@panel_drv/__overlay__/panel_drv_0/gpios/conn-det";
		pcd = "/fragment@panel_drv/__overlay__/panel_drv_0/gpios/pcd";
		ddi_vci = "/fragment@panel_drv/__overlay__/panel_drv_0/regulators/ddi-vci";
		ddi_vdd3 = "/fragment@panel_drv/__overlay__/panel_drv_0/regulators/ddi-vdd3";
		mtkfb_pins_lcm_led_en1 = "/fragment@3/__overlay__/lcm_led_en1_gpio";
		mtkfb_pins_lcm_led_en0 = "/fragment@3/__overlay__/lcm_led_en0_gpio";
		mtkfb_pins_lcm_rst_out1_gpio = "/fragment@3/__overlay__/lcm_rst_out1_gpio";
		mtkfb_pins_lcm_rst_out0_gpio = "/fragment@3/__overlay__/lcm_rst_out0_gpio";
		mtkfb_pins_lcm_dsi_te = "/fragment@3/__overlay__/lcm_dsi_te";
		panel_in = "/fragment@6/__overlay__/panel@0/port/endpoint";
		dsi_out = "/fragment@6/__overlay__/ports/port/endpoint";
		gps_pins_default = "/fragment@7/__overlay__/gps_default";
		gps_l1_lna_pins_ol = "/fragment@7/__overlay__/gps_l1_lna@0";
		gps_l1_lna_pins_dsp_ctrl = "/fragment@7/__overlay__/gps_l1_lna@1";
		gps_l1_lna_pins_oh = "/fragment@7/__overlay__/gps_l1_lna@2";
		gps_l5_lna_pins_ol = "/fragment@7/__overlay__/gps_l5_lna@0";
		gps_l5_lna_pins_dsp_ctrl = "/fragment@7/__overlay__/gps_l5_lna@1";
		gps_l5_lna_pins_oh = "/fragment@7/__overlay__/gps_l5_lna@2";
		lm3643 = "/fragment@9/__overlay__/lm3643@63";
		fl_core_0 = "/fragment@9/__overlay__/lm3643@63/flash@0/port@0/endpoint";
		fl_core_1 = "/fragment@9/__overlay__/lm3643@63/flash@1/port@1/endpoint";
		lm3643_pins_default = "/fragment@10/__overlay__/default";
		lm3643_pins_hwen_high = "/fragment@10/__overlay__/hwen_high";
		lm3643_pins_hwen_low = "/fragment@10/__overlay__/hwen_low";
		flashlight_0 = "/fragment@11/__overlay__/port@0/endpoint";
		flashlight_1 = "/fragment@11/__overlay__/port@1/endpoint";
		camera_main_af_mtk = "/fragment@12/__overlay__/camera_main_af@72";
		camera_main_two_af_mtk = "/fragment@13/__overlay__/camera_main_two_af@0d";
		camera_main_three_af_mtk = "/fragment@13/__overlay__/camera_main_three_af@0c";
		mtee = "/fragment@22/__overlay__/MTEE";
		svp = "/fragment@22/__overlay__/SecureVideoPath";
		s2mpb03_pmic_0 = "/fragment@36/__overlay__/s2mpb03_pmic@56";
		s2mpb03_0_l1 = "/fragment@36/__overlay__/s2mpb03_pmic@56/regulators/s2mpb03-ldo1";
		s2mpb03_0_l2 = "/fragment@36/__overlay__/s2mpb03_pmic@56/regulators/s2mpb03-ldo2";
		s2mpb03_0_l3 = "/fragment@36/__overlay__/s2mpb03_pmic@56/regulators/s2mpb03-ldo3";
		s2mpb03_0_l4 = "/fragment@36/__overlay__/s2mpb03_pmic@56/regulators/s2mpb03-ldo4";
		s2mpb03_0_l5 = "/fragment@36/__overlay__/s2mpb03_pmic@56/regulators/s2mpb03-ldo5";
		s2mpb03_0_l6 = "/fragment@36/__overlay__/s2mpb03_pmic@56/regulators/s2mpb03-ldo6";
		s2mpb03_0_l7 = "/fragment@36/__overlay__/s2mpb03_pmic@56/regulators/s2mpb03-ldo7";
		gpio_i2c_0_sda_default = "/fragment@37/__overlay__/gpio_i2c_0_sda/gpio_i2c_0_sda_default";
		gpio_i2c_0_scl_default = "/fragment@38/__overlay__/gpio_i2c_0_scl/gpio_i2c_0_scl_default";
		gfspi_drdypin_active = "/fragment@39/__overlay__/gfspi_drdypin_active";
		gfspi_drdypin_suspend = "/fragment@39/__overlay__/gfspi_drdypin_suspend";
		gfspi_rstpin = "/fragment@40/__overlay__/gfspi_rstpin";
		gfspi_ldopin = "/fragment@41/__overlay__/gfspi_ldopin";
		fps_set_miso = "/fragment@42/__overlay__/set_miso";
		fps_set_cs = "/fragment@42/__overlay__/set_cs";
		fps_set_mosi = "/fragment@42/__overlay__/set_mosi";
		fps_set_clk = "/fragment@42/__overlay__/set_clk";
		fps_clr_miso = "/fragment@42/__overlay__/clr_miso";
		fps_clr_cs = "/fragment@42/__overlay__/clr_cs";
		fps_clr_mosi = "/fragment@42/__overlay__/clr_mosi";
		fps_clr_clk = "/fragment@42/__overlay__/clr_clk";
		sm5461_charger = "/fragment@43/__overlay__/sm5461@63";
		if_pmic_irq = "/fragment@44/__overlay__/if_pmic_irq";
		usbpd_irq = "/fragment@44/__overlay__/usbpd_irq";
		mst_pwr_en = "/fragment@47/__overlay__/sec-mst,mst-pwr-gpio";
		ldo_gpio4 = "/fragment@51/__overlay__/ldo_gpio4";
		ldo_gpio1 = "/fragment@52/__overlay__/ldo_gpio1";
		ldo_gpio2 = "/fragment@53/__overlay__/ldo_gpio2";
		ldo_gpio3 = "/fragment@54/__overlay__/ldo_gpio3";
		ldo_gpio0 = "/fragment@55/__overlay__/ldo_gpio0";
		tsp_int = "/fragment@56/__overlay__/tsp_int";
		tsp_zxt = "/fragment@57/__overlay__/touchscreen@20";
		snvm_i2c_on = "/fragment@58/__overlay__/snvm_i2c_on";
		snvm_i2c_off = "/fragment@58/__overlay__/snvm_i2c_off";
		disp_rst_default = "/fragment@60/__overlay__/disp-rst-default";
		disp_det_default = "/fragment@61/__overlay__/disp_det_default";
		conn_det_default = "/fragment@62/__overlay__/conn_det_default";
		pcd_default = "/fragment@63/__overlay__/pcd_default";
		grip_i2c_sda = "/fragment@64/__overlay__/grip-i2c-sda";
		grip_i2c_scl = "/fragment@64/__overlay__/grip-i2c-scl";
		grip_int = "/fragment@65/__overlay__/grip-int";
		grip_ldo_en = "/fragment@67/__overlay__/grip-ldo-en";
		ts_int_active = "/fragment@68/__overlay__/ts_int_active";
		ts_int_suspend = "/fragment@68/__overlay__/ts_int_suspend";
		tsp_focaltech = "/fragment@69/__overlay__/touchscreen@38";
		tsp_i2c_sda_default = "/fragment@70/__overlay__/tsp_i2c_sda_default";
		tsp_i2c_scl_default = "/fragment@70/__overlay__/tsp_i2c_scl_default";
		nfc_ven = "/fragment@72/__overlay__/nfc_ven";
		ven_nc = "/fragment@72/__overlay__/ven_nc";
		nfc_firm = "/fragment@73/__overlay__/nfc_firm";
		firm_nc = "/fragment@73/__overlay__/firm_nc";
		nfc_clk_req = "/fragment@74/__overlay__/nfc_clk_req";
		clk_req_nc = "/fragment@74/__overlay__/clk_req_nc";
		nfc_irq = "/fragment@75/__overlay__/nfc_irq";
		irq_nc = "/fragment@75/__overlay__/irq_nc";
		nfc_i2c_off = "/fragment@76/__overlay__/nfc_i2c_off";
		nfc_i2c_on = "/fragment@76/__overlay__/nfc_i2c_on";
		nfc_check = "/fragment@77/__overlay__/nfc_check";
		rt5133 = "/fragment@79/__overlay__/rt5133@18";
		aw88230_amp = "/fragment@80/__overlay__/aw88230_amp@34";
		camera0_mclk_2mA = "/fragment@87/__overlay__/camera0_mclk_2mA@gpio126";
		camera0_mclk_4mA = "/fragment@87/__overlay__/camera0_mclk_4mA@gpio126";
		camera0_mclk_6mA = "/fragment@87/__overlay__/camera0_mclk_6mA@gpio126";
		camera0_mclk_8mA = "/fragment@87/__overlay__/camera0_mclk_8mA@gpio126";
		camera0_mclk_off = "/fragment@87/__overlay__/camera0_mclk_gpio_mode@gpio126";
		camera0_rst_low = "/fragment@87/__overlay__/camera0_rst_output_low@gpio16";
		camera0_rst_high = "/fragment@87/__overlay__/camera0_rst_output_high@gpio16";
		camera_main_i2c_scl_on = "/fragment@87/__overlay__/camera_main_i2c_scl_on@gpio146";
		camera_main_i2c_sda_on = "/fragment@87/__overlay__/camera_main_i2c_sda_on@gpio147";
		camera_main_i2c_scl_off = "/fragment@87/__overlay__/camera_main_i2c_scl_off@gpio146";
		camera_main_i2c_sda_off = "/fragment@87/__overlay__/camera_main_i2c_sda_off@gpio147";
		camera1_mclk_2mA = "/fragment@87/__overlay__/camera1_mclk_2mA@gpio129";
		camera1_mclk_4mA = "/fragment@87/__overlay__/camera1_mclk_4mA@gpio129";
		camera1_mclk_6mA = "/fragment@87/__overlay__/camera1_mclk_6mA@gpio129";
		camera1_mclk_8mA = "/fragment@87/__overlay__/camera1_mclk_8mA@gpio129";
		camera1_mclk_off = "/fragment@87/__overlay__/camera1_mclk_gpio_mode@gpio129";
		camera1_rst_low = "/fragment@87/__overlay__/camera1_rst_output_low@gpio15";
		camera1_rst_high = "/fragment@87/__overlay__/camera1_rst_output_high@gpio15";
		camera_sub_i2c_scl_on = "/fragment@87/__overlay__/camera_sub_i2c_scl_on@gpio138";
		camera_sub_i2c_sda_on = "/fragment@87/__overlay__/camera_sub_i2c_sda_on@gpio139";
		camera_sub_i2c_scl_off = "/fragment@87/__overlay__/camera_sub_i2c_scl_off@gpio138";
		camera_sub_i2c_sda_off = "/fragment@87/__overlay__/camera_sub_i2c_sda_off@gpio139";
		camera2_mclk_2mA = "/fragment@87/__overlay__/camera2_mclk_2mA@gpio127";
		camera2_mclk_4mA = "/fragment@87/__overlay__/camera2_mclk_4mA@gpio127";
		camera2_mclk_6mA = "/fragment@87/__overlay__/camera2_mclk_6mA@gpio127";
		camera2_mclk_8mA = "/fragment@87/__overlay__/camera2_mclk_8mA@gpio127";
		camera2_mclk_off = "/fragment@87/__overlay__/camera2_mclk_gpio_mode@gpio127";
		camera2_rst_low = "/fragment@87/__overlay__/camera2_rst_output_low@gpio18";
		camera2_rst_high = "/fragment@87/__overlay__/camera2_rst_output_high@gpio18";
		camera_main_two_i2c_scl_on = "/fragment@87/__overlay__/camera_main_two_i2c_scl_on@gpio134";
		camera_main_two_i2c_sda_on = "/fragment@87/__overlay__/camera_main_two_i2c_sda_on@gpio135";
		camera_main_two_i2c_scl_off = "/fragment@87/__overlay__/camera_main_two_i2c_scl_off@gpio134";
		camera_main_two_i2c_sda_off = "/fragment@87/__overlay__/camera_main_two_i2c_sda_off@gpio135";
		camera3_mclk_2mA = "/fragment@87/__overlay__/camera3_mclk_2mA@gpio128";
		camera3_mclk_4mA = "/fragment@87/__overlay__/camera3_mclk_4mA@gpio128";
		camera3_mclk_6mA = "/fragment@87/__overlay__/camera3_mclk_6mA@gpio128";
		camera3_mclk_8mA = "/fragment@87/__overlay__/camera3_mclk_8mA@gpio128";
		camera3_mclk_off = "/fragment@87/__overlay__/camera3_mclk_gpio_mode@gpio128";
		camera3_rst_low = "/fragment@87/__overlay__/camera3_rst_output_low@gpio22";
		camera3_rst_high = "/fragment@87/__overlay__/camera3_rst_output_high@gpio22";
		camera_main_four_i2c_scl_on = "/fragment@87/__overlay__/camera_main_four_i2c_scl_on@gpio134";
		camera_main_four_i2c_sda_on = "/fragment@87/__overlay__/camera_main_four_i2c_sda_on@gpio135";
		camera_main_four_i2c_scl_off = "/fragment@87/__overlay__/camera_main_four_i2c_scl_off@gpio134";
		camera_main_four_i2c_sda_off = "/fragment@87/__overlay__/camera_main_four_i2c_sda_off@gpio135";
		camera_i2c2_pullup_2k = "/fragment@87/__overlay__/camera_i2c2_pull_up_2k";
		camera_pins_default = "/fragment@87/__overlay__/camdefault";
		camera_main_two_mtk = "/fragment@89/__overlay__/camera_main_two@6C";
		camera_main_three_mtk = "/fragment@89/__overlay__/camera_main_three@20";
		mtk_camera_eeprom2 = "/fragment@89/__overlay__/camera_eeprom2@B6";
		mtk_camera_eeprom3 = "/fragment@89/__overlay__/camera_eeprom3@A4";
		camera_sub_mtk = "/fragment@90/__overlay__/camera_sub@72";
		mtk_camera_eeprom1 = "/fragment@90/__overlay__/camera_eeprom1@A2";
		camera_main_mtk = "/fragment@91/__overlay__/camera_main@AC";
		mtk_camera_eeprom0 = "/fragment@91/__overlay__/camera_eeprom0@A0";
	};

	__fixups__ {
		auxadc = "/fragment@smd/__overlay__/samsung_mobile_device/battery:io-channels:0\0/fragment@smd/__overlay__/samsung_mobile_device/battery:io-channels:8\0/fragment@smd/__overlay__/samsung_mobile_device/battery:io-channels:16\0/fragment@smd/__overlay__/samsung_mobile_device/sec_thermistor@2:io-channels:0\0/fragment@smd/__overlay__/samsung_mobile_device/sec_thermistor@0:io-channels:0\0/fragment@smd/__overlay__/samsung_mobile_device/sec_thermistor@1:io-channels:0";
		pio = "/fragment@smd/__overlay__/samsung_mobile_device/sm5714-fuelgauge:fuelgauge,bat_id_gpio:0\0/fragment@smd/__overlay__/samsung_mobile_device/sm5714-fuelgauge:fuelgauge,bat_id_gpio:12\0/fragment@smd/__overlay__/samsung_mobile_device/sec-mst:sec-mst,mst-pwr-gpio:0\0/fragment@smd/__overlay__/samsung_mobile_device/fixed_regulator@4:gpio:0\0/fragment@smd/__overlay__/samsung_mobile_device/fixed_regulator@1:gpio:0\0/fragment@smd/__overlay__/samsung_mobile_device/fixed_regulator@2:gpio:0\0/fragment@smd/__overlay__/samsung_mobile_device/fixed_regulator@3:gpio:0\0/fragment@smd/__overlay__/samsung_mobile_device/fixed_regulator@0:gpio:0\0/fragment@smd/__overlay__/gw3x:goodix,gpio_pwr:0\0/fragment@smd/__overlay__/gw3x:goodix,gpio_reset:0\0/fragment@smd/__overlay__/gw3x:goodix,gpio_irq:0\0/fragment@model/__overlay__/shub:mag-check-nfc:0\0/fragment@model/__overlay__/i2c@30:gpios:0\0/fragment@model/__overlay__/i2c@30:gpios:12\0/fragment@model/__overlay__/i2c@30/sx9385-i2c@29:interrupt-parent:0\0/fragment@model/__overlay__/i2c@30/sx9385-i2c@29:sx9385,ldo_en:0\0/fragment@model/__overlay__/i2c@30/sx9385-i2c@29:sx9385,nirq-gpio:0\0/fragment@panel_drv/__overlay__/panel_drv_0/gpios/disp-reset:gpios:0\0/fragment@panel_drv/__overlay__/panel_drv_0/gpios/disp-det:gpios:0\0/fragment@panel_drv/__overlay__/panel_drv_0/gpios/conn-det:gpios:0\0/fragment@panel_drv/__overlay__/panel_drv_0/gpios/pcd:gpios:0\0/fragment@3:target:0\0/fragment@6/__overlay__/panel@0:reset-gpios:0\0/fragment@6/__overlay__/panel@0:tsp-3p0-en-gpios:0\0/fragment@6/__overlay__/panel@0:lcd-3p0-en-gpios:0\0/fragment@6/__overlay__/panel@0:lcd-1p8-en-gpios:0\0/fragment@7:target:0\0/fragment@10:target:0\0/fragment@25/__overlay__:GPIO_SIM1_HOT_PLUG:0\0/fragment@25/__overlay__:GPIO_SIM1_SCLK:0\0/fragment@25/__overlay__:GPIO_SIM1_SRST:0\0/fragment@25/__overlay__:GPIO_SIM1_SIO:0\0/fragment@25/__overlay__:GPIO_SIM2_SCLK:0\0/fragment@25/__overlay__:GPIO_SIM2_SRST:0\0/fragment@25/__overlay__:GPIO_SIM2_SIO:0\0/fragment@25/__overlay__:GPIO_FDD_BAND_SUPPORT_DETECT_1ST_PIN:0\0/fragment@25/__overlay__:GPIO_FDD_BAND_SUPPORT_DETECT_2ND_PIN:0\0/fragment@25/__overlay__:GPIO_FDD_BAND_SUPPORT_DETECT_3RD_PIN:0\0/fragment@27/__overlay__:interrupt-parent:0\0/fragment@28/__overlay__:interrupt-parent:0\0/fragment@29/__overlay__:interrupt-parent:0\0/fragment@30/__overlay__:interrupt-parent:0\0/fragment@31/__overlay__:cd-gpios:0\0/fragment@37:target:0\0/fragment@38:target:0\0/fragment@39:target:0\0/fragment@40:target:0\0/fragment@41:target:0\0/fragment@42:target:0\0/fragment@44:target:0\0/fragment@45/__overlay__/sm5714@49:sm5714,irq-gpio:0\0/fragment@46/__overlay__/usbpd-sm5714@33:usbpd,usbpd_int:0\0/fragment@47:target:0\0/fragment@51:target:0\0/fragment@52:target:0\0/fragment@53:target:0\0/fragment@54:target:0\0/fragment@55:target:0\0/fragment@56:target:0\0/fragment@57/__overlay__/touchscreen@20:sec,irq_gpio:0\0/fragment@58:target:0\0/fragment@60:target:0\0/fragment@61:target:0\0/fragment@62:target:0\0/fragment@63:target:0\0/fragment@64:target:0\0/fragment@65:target:0\0/fragment@66:target:0\0/fragment@67:target:0\0/fragment@68:target:0\0/fragment@69/__overlay__/touchscreen@38:sec,irq_gpio:0\0/fragment@70:target:0\0/fragment@72:target:0\0/fragment@73:target:0\0/fragment@74:target:0\0/fragment@75:target:0\0/fragment@76:target:0\0/fragment@77:target:0\0/fragment@78/__overlay__/pn547@2B:interrupt-parent:0\0/fragment@78/__overlay__/pn547@2B:pn547,irq-gpio:0\0/fragment@78/__overlay__/pn547@2B:pn547,ven-gpio:0\0/fragment@78/__overlay__/pn547@2B:pn547,firm-gpio:0\0/fragment@78/__overlay__/pn547@2B:pn547,clk_req-gpio:0\0/fragment@78/__overlay__/pn547@2B:pn547,nfc-det-gpio:0\0/fragment@80/__overlay__/aw88230_amp@34:irq-gpio:0\0/fragment@87:target:0\0/fragment@92/__overlay__/sm5714@49/sm5714-fled:flash-en-gpio:0\0/fragment@92/__overlay__/sm5714@49/sm5714-fled:torch-en-gpio:0";
		mt6358_vibr_reg = "/fragment@smd/__overlay__/samsung_mobile_device/dc_vibrator:dc_vib-supply:0\0/fragment@48:target:0";
		topckgen_clk = "/fragment@smd/__overlay__/gw3x:clocks:0\0/fragment@smd/__overlay__/gw3x:clocks:8";
		infracfg_ao_clk = "/fragment@smd/__overlay__/gw3x:clocks:16";
		chosen = "/fragment@0:target:0";
		accdet = "/fragment@1:target:0\0/fragment@84:target:0";
		mtk_leds = "/fragment@2:target:0";
		mtkfb = "/fragment@4:target:0";
		dispsys_config = "/fragment@5:target:0";
		dsi0 = "/fragment@6:target:0\0/fragment@85:target:0";
		gps = "/fragment@8:target:0";
		i2c6 = "/fragment@9:target:0\0/fragment@78:target:0";
		mtk_composite_v4l2_1 = "/fragment@11:target:0";
		i2c8 = "/fragment@12:target:0\0/fragment@91:target:0";
		i2c2 = "/fragment@13:target:0\0/fragment@89:target:0";
		camera_af_hw_node = "/fragment@14:target:0";
		rt5133_ldo3 = "/fragment@14/__overlay__:camaf_m1_pmic-supply:0";
		rt5133_gpio1 = "/fragment@14/__overlay__:camaf_m2_pmic-supply:0\0/fragment@14/__overlay__:camaf_m3_pmic-supply:0";
		snd_scp_audio = "/fragment@15:target:0\0/fragment@83:target:0";
		sound = "/fragment@16:target:0\0/fragment@82:target:0";
		scp_audio_mbox = "/fragment@17:target:0";
		pdc = "/fragment@18:target:0";
		tboard_thermistor1 = "/fragment@19:target:0";
		mtk_gauge = "/fragment@20:target:0";
		lk_charger = "/fragment@21:target:0";
		mtee_svp = "/fragment@22:target:0";
		mmc0 = "/fragment@23:target:0";
		mmc1 = "/fragment@24:target:0\0/fragment@31:target:0";
		mt6358_vmch_eint_low = "/fragment@24/__overlay__:vmmc-supply:0";
		gpio_usage_mapping = "/fragment@25:target:0";
		gpio = "/fragment@26:target:0";
		subpmic_pmu_eint = "/fragment@27:target:0";
		smart_pa = "/fragment@28:target:0";
		touch = "/fragment@29:target:0";
		dsi_te = "/fragment@30:target:0";
		md1_sim1_hot_plug_eint = "/fragment@32:target:0";
		md1_sim2_hot_plug_eint = "/fragment@33:target:0";
		mt6366keys = "/fragment@34:target:0";
		keypad = "/fragment@35:target:0";
		i2c9 = "/fragment@36:target:0";
		i2c0 = "/fragment@43:target:0\0/fragment@45:target:0\0/fragment@46:target:0\0/fragment@92:target:0";
		mt6358_vbif28_reg = "/fragment@49:target:0";
		mt6358_vio28_reg = "/fragment@50:target:0";
		i2c7 = "/fragment@57:target:0\0/fragment@69:target:0\0/fragment@71:target:0";
		i2c5 = "/fragment@59:target:0\0/fragment@79:target:0";
		i2c3 = "/fragment@80:target:0";
		aud_dat_mosi_off = "/fragment@81:target:0";
		ufshci = "/fragment@86:target:0";
		kd_camera_hw1 = "/fragment@88:target:0";
		i2c4 = "/fragment@90:target:0";
	};

	__local_fixups__ {

		fragment@smd {

			__overlay__ {

				samsung_mobile_device {

					sec-mst {
						pinctrl-0 = <0x00>;
					};

					fixed_regulator@4 {
						pinctrl-0 = <0x00>;
					};

					fixed_regulator@1 {
						pinctrl-0 = <0x00>;
					};

					fixed_regulator@2 {
						pinctrl-0 = <0x00>;
					};

					fixed_regulator@3 {
						pinctrl-0 = <0x00>;
					};

					fixed_regulator@0 {
						pinctrl-0 = <0x00>;
					};
				};

				gw3x {
					pinctrl-0 = <0x00 0x04 0x08>;
					pinctrl-1 = <0x00 0x04 0x08 0x0c 0x10>;
					pinctrl-2 = <0x00 0x04 0x08 0x0c 0x10>;
					pinctrl-3 = <0x00>;
					pinctrl-4 = <0x00>;
				};
			};
		};

		fragment@model {

			__overlay__ {

				i2c@30 {
					pinctrl-0 = <0x00 0x04>;

					sx9385-i2c@29 {
						pinctrl-0 = <0x00 0x04>;
					};
				};
			};
		};

		fragment@panel_display_mode {

			__overlay__ {

				a15_panel_display_modes {
					native-mode = <0x00>;
					exposed-mode = <0x00 0x04>;

					a15_panel_display_mode_1080x2340_90hs {
						dsc_picture_parameter_set = <0x00>;
					};

					a15_panel_display_mode_1080x2340_60hs {
						dsc_picture_parameter_set = <0x00>;
					};
				};
			};
		};

		fragment@panel_drv {

			__overlay__ {

				panel_drv_0 {
					pinctrl-0 = <0x00 0x04 0x08>;

					s6e8fc3_a15_power_ctrl {

						actions {

							vci-on {
								reg = <0x00>;
							};

							vdd3-on {
								reg = <0x00>;
							};

							vci-off {
								reg = <0x00>;
							};

							vdd3-off {
								reg = <0x00>;
							};

							reset-high {
								gpio = <0x00>;
							};

							reset-low {
								gpio = <0x00>;
							};
						};

						sequences {
							panel_boot_on = <0x00 0x04>;
							panel_power_on = <0x00 0x04 0x08 0x0c 0x10 0x14 0x18 0x1c 0x20 0x24>;
							panel_power_off = <0x00 0x04 0x08 0x0c 0x10>;
						};
					};

					panels {

						s6e8fc3_a15 {
							ap-vendor-setting = <0x00>;
							display-mode = <0x00>;
							power-ctrl = <0x00>;
						};
					};

					panel-lut {
						panel_0 = <0x00>;
					};

					regulators {

						ddi-vci {
							regulator = <0x00>;
						};

						ddi-vdd3 {
							regulator = <0x00>;
						};
					};
				};
			};
		};

		fragment@4 {

			__overlay__ {
				pinctrl-0 = <0x00>;
				pinctrl-1 = <0x00>;
				pinctrl-2 = <0x00>;
				pinctrl-3 = <0x00>;
				pinctrl-4 = <0x00>;
			};
		};

		fragment@5 {

			__overlay__ {
				pinctrl-0 = <0x00>;
				pinctrl-1 = <0x00>;
				pinctrl-2 = <0x00>;
			};
		};

		fragment@6 {

			__overlay__ {

				panel@0 {

					port {

						endpoint {
							remote-endpoint = <0x00>;
						};
					};
				};

				ports {

					port {

						endpoint {
							remote-endpoint = <0x00>;
						};
					};
				};
			};
		};

		fragment@8 {

			__overlay__ {
				pinctrl-0 = <0x00>;
				pinctrl-1 = <0x00>;
				pinctrl-2 = <0x00>;
				pinctrl-3 = <0x00>;
				pinctrl-4 = <0x00>;
				pinctrl-5 = <0x00>;
				pinctrl-6 = <0x00>;
			};
		};

		fragment@9 {

			__overlay__ {

				lm3643@63 {
					pinctrl-0 = <0x00>;
					pinctrl-1 = <0x00>;
					pinctrl-2 = <0x00>;

					flash@0 {

						port@0 {

							endpoint {
								remote-endpoint = <0x00>;
							};
						};
					};

					flash@1 {

						port@1 {

							endpoint {
								remote-endpoint = <0x00>;
							};
						};
					};
				};
			};
		};

		fragment@11 {

			__overlay__ {

				port@0 {

					endpoint {
						remote-endpoint = <0x00>;
					};
				};

				port@1 {

					endpoint {
						remote-endpoint = <0x00>;
					};
				};
			};
		};

		fragment@45 {

			__overlay__ {

				sm5714@49 {
					pinctrl-0 = <0x00>;
				};
			};
		};

		fragment@46 {

			__overlay__ {

				usbpd-sm5714@33 {
					pinctrl-0 = <0x00>;
				};
			};
		};

		fragment@57 {

			__overlay__ {

				touchscreen@20 {
					pinctrl-0 = <0x00>;
					pinctrl-1 = <0x00>;
					tsp_avdd_ldo-supply = <0x00>;
				};
			};
		};

		fragment@59 {

			__overlay__ {
				pinctrl-0 = <0x00>;
				pinctrl-1 = <0x00>;
				pinctrl-2 = <0x00>;

				k250a@23 {
					1p8_pvdd-supply = <0x00>;
				};
			};
		};

		fragment@69 {

			__overlay__ {

				touchscreen@38 {
					pinctrl-0 = <0x00>;
					pinctrl-1 = <0x00>;
					tsp_avdd_ldo-supply = <0x00>;
				};
			};
		};

		fragment@71 {

			__overlay__ {
				pinctrl-0 = <0x00 0x04>;
			};
		};

		fragment@78 {

			__overlay__ {

				pn547@2B {
					nfc_pvdd-supply = <0x00>;
					pinctrl-0 = <0x00 0x04 0x08 0x0c 0x10 0x14>;
					pinctrl-1 = <0x00 0x04 0x08 0x0c 0x10>;
					pinctrl-2 = <0x00>;
				};
			};
		};

		fragment@82 {

			__overlay__ {

				mediatek,speaker-codec {
					sound-dai = <0x00>;
				};
			};
		};

		fragment@88 {

			__overlay__ {
				pinctrl-0 = <0x00>;
				pinctrl-1 = <0x00>;
				pinctrl-2 = <0x00>;
				pinctrl-3 = <0x00>;
				pinctrl-4 = <0x00>;
				pinctrl-5 = <0x00>;
				pinctrl-6 = <0x00>;
				pinctrl-7 = <0x00>;
				pinctrl-8 = <0x00>;
				pinctrl-9 = <0x00>;
				pinctrl-10 = <0x00>;
				pinctrl-11 = <0x00>;
				pinctrl-12 = <0x00>;
				pinctrl-13 = <0x00>;
				pinctrl-14 = <0x00>;
				pinctrl-15 = <0x00>;
				pinctrl-16 = <0x00>;
				pinctrl-17 = <0x00>;
				pinctrl-18 = <0x00>;
				pinctrl-19 = <0x00>;
				pinctrl-20 = <0x00>;
				pinctrl-21 = <0x00>;
				pinctrl-22 = <0x00>;
				pinctrl-23 = <0x00>;
				pinctrl-24 = <0x00>;
				pinctrl-25 = <0x00>;
				pinctrl-26 = <0x00>;
				pinctrl-27 = <0x00>;
				pinctrl-28 = <0x00>;
				cam0_vcamd-supply = <0x00>;
				cam0_vcama-supply = <0x00>;
				cam0_vcamio-supply = <0x00>;
				cam0_vcamaf-supply = <0x00>;
				cam1_vcamd-supply = <0x00>;
				cam1_vcama-supply = <0x00>;
				cam1_vcamio-supply = <0x00>;
				cam1_vcamd1-supply = <0x00>;
				cam2_vcamd-supply = <0x00>;
				cam2_vcama-supply = <0x00>;
				cam2_vcamio-supply = <0x00>;
				cam3_vcama-supply = <0x00>;
				cam3_vcamio-supply = <0x00>;
				cam3_vcamd1-supply = <0x00>;
			};
		};

		fragment@89 {

			__overlay__ {
				pinctrl-0 = <0x00>;
			};
		};
	};
};
